VERSION ""

NS_ :

BS_:

BU_: Gateway EPS IBC RBU RWS PDCR

BO_ 256 ADV_2: 32 Gateway
 SG_ Checksum_ADV_2 : 0|8@1+ (1,0) [0|255] ""  EPS,IBC
 SG_ ADV_ErrorSt_EPS : 8|1@1+ (1,0) [0|1] ""  EPS
 SG_ ADV_AutoParkingModeReq : 9|3@1+ (1,0) [0|7] ""  EPS,PDCR
 SG_ ADV_AutoParkingRequestSt : 12|2@1+ (1,0) [0|3] ""  EPS,PDCR
 SG_ APA_DriverInterventionSt : 15|1@1+ (1,0) [0|1] ""  IBC
 SG_ ADV_ErrorSt_APA : 16|2@1+ (1,0) [0|3] ""  EPS
 SG_ ADV_ErrorSt_RPA : 18|2@1+ (1,0) [0|3] ""  EPS
 SG_ ADV_ErrorSt_AVP : 20|2@1+ (1,0) [0|3] ""  EPS
 SG_ ADV_ErrorSt_RVA : 22|2@1+ (1,0) [0|3] "" Vector__XXX
 SG_ ADV_WorkingSt_APA : 24|3@1+ (1,0) [0|7] ""  EPS
 SG_ ADV_WorkingSt_RPA : 27|3@1+ (1,0) [0|7] ""  EPS
 SG_ ADV_WorkingSt_AVP : 32|3@1+ (1,0) [0|7] ""  EPS
 SG_ APA_SecureRequest : 35|1@1+ (1,0) [0|1] ""  IBC
 SG_ APA_AutoParkingReq : 36|1@1+ (1,0) [0|1] ""  IBC,PDCR
 SG_ APA_DirectionCmd : 37|2@1+ (1,0) [0|3] ""  IBC
 SG_ ADV_SteeringWheelAngleRequest : 40|15@1+ (0.04375,0) [0|1433.55625] "°„"  EPS
 SG_ ADV_SteeringWheelAngleSignReques : 56|2@1+ (1,0) [0|3] ""  EPS
 SG_ ADV_SteeringWheelAngleControlReq : 58|2@1+ (1,0) [0|3] ""  EPS
 SG_ ADV_RearWheelAngleRequestSt : 62|2@1+ (1,0) [0|3] "" Vector__XXX
 SG_ ADV_RearWheelAngleRequest : 64|12@1+ (0.01,-20.48) [-20.48|20.47] "°„" Vector__XXX
 SG_ APA_BrakeFunctionMode : 76|4@1+ (1,0) [0|15] ""  IBC,PDCR
 SG_ APA_StopDistance : 80|12@1+ (1,0) [0|4095] "cm"  IBC
 SG_ APA_SpeedLimitation : 96|8@1+ (0.1,0) [0|15] "km/h"  IBC
 SG_ APA_FailureBrakeMode : 104|3@1+ (1,0) [0|7] ""  IBC
 SG_ LiveCounter_ADV_2 : 188|4@1+ (1,0) [0|15] "Pulse"  EPS,IBC
 SG_ SECOC_FV_ADV_2 : 192|16@1+ (1,0) [0|0] ""  IBC
 SG_ SECOC_TMAC_ADV_2 : 208|48@1+ (1,0) [0|0] ""  IBC

BO_ 546 ATC_2: 8 Gateway
 SG_ AmbientTemp : 24|8@1+ (0.5,-40) [-40|87.5] "°„C"  IBC

BO_ 586 DDCU_1: 8 Gateway
 SG_ DoorSt_FL : 2|1@1+ (1,0) [0|1] ""  IBC

BO_ 532 DMS_1: 8 Gateway
 SG_ DMS_ESCModeChangeCmd : 16|4@1+ (1,0) [0|15] ""  IBC
 SG_ DMS_EPSModeChangeCmd : 20|2@1+ (1,0) [0|3] ""  EPS

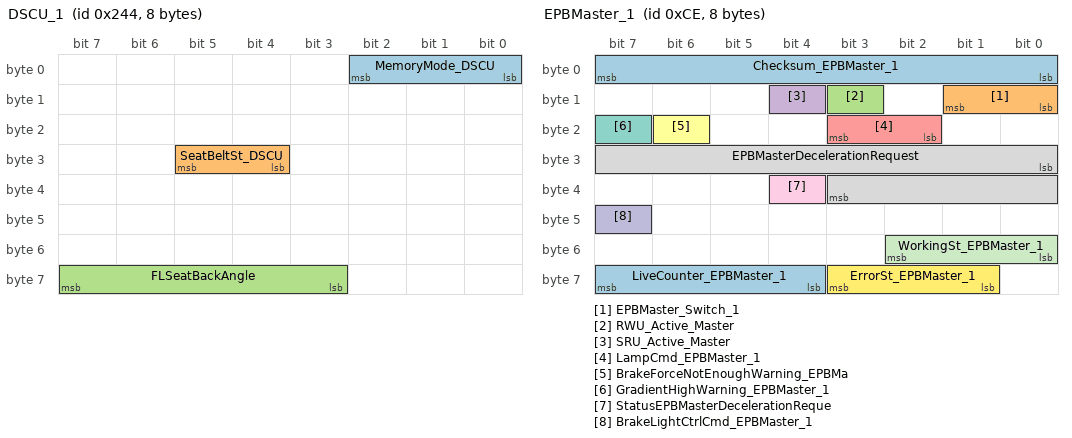
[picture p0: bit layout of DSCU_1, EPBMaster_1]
BO_ 580 DSCU_1: 8 Gateway
 SG_ MemoryMode_DSCU : 0|3@1+ (1,0) [0|7] "" Vector__XXX
 SG_ SeatBeltSt_DSCU : 28|2@1+ (1,0) [0|3] ""  IBC
 SG_ FLSeatBackAngle : 59|5@1+ (5,0) [0|100] "%" Vector__XXX

BO_ 233 EPBMasterReqToS: 8 Gateway
 SG_ PbcOutActuatorState_M : 8|3@1+ (1,0) [0|7] ""  PDCR
 SG_ PbcOutPadAdjustmentRequest_M : 12|1@1+ (1,0) [0|1] ""  PDCR
 SG_ PbcInHostAvailability_M : 13|2@1+ (1,0) [0|3] ""  PDCR
 SG_ PbcInApplyReleaseRequest_M : 16|4@1+ (1,0) [0|15] ""  PDCR
 SG_ PbcInRollerbenchActive_M : 20|1@1+ (1,0) [0|1] ""  PDCR
 SG_ PbcInDriveAwayIntentionIndicatio : 21|1@1+ (1,0) [0|1] ""  PDCR
 SG_ PbcEnableLineLock_M : 22|1@1+ (1,0) [0|1] ""  PDCR
 SG_ PbcEnableLineRelease_M : 23|1@1+ (1,0) [0|1] ""  PDCR
 SG_ EpbDegradedMode_M : 24|3@1+ (1,0) [0|7] ""  PDCR
 SG_ PbcDynApplyControlState_M : 28|4@1+ (1,0) [0|15] ""  PDCR
 SG_ PbcRollerbenchApplyControlState_ : 32|4@1+ (1,0) [0|15] ""  PDCR
 SG_ IsRelTchPt_M : 37|1@1+ (1,0) [0|1] ""  PDCR
 SG_ IsRWAAppEn_M : 38|1@1+ (1,0) [0|1] ""  PDCR
 SG_ IsRWARelEn_M : 39|1@1+ (1,0) [0|1] ""  PDCR
 SG_ RWACntrStpApp_M : 40|8@1+ (1,0) [0|255] "pulse"  PDCR
 SG_ CntrRWAAppHld_M : 48|8@1+ (1,0) [0|255] "pulse"  PDCR
 SG_ PbcRWAControlState_M : 56|4@1+ (1,0) [0|15] ""  PDCR

BO_ 206 EPBMaster_1: 8 Gateway
 SG_ Checksum_EPBMaster_1 : 0|8@1+ (1,0) [0|255] ""  IBC
 SG_ EPBMaster_Switch_1 : 8|2@1+ (1,0) [0|3] ""  IBC
 SG_ RWU_Active_Master : 11|1@1+ (1,0) [0|1] "" Vector__XXX
 SG_ SRU_Active_Master : 12|1@1+ (1,0) [0|1] "" Vector__XXX
 SG_ LampCmd_EPBMaster_1 : 18|2@1+ (1,0) [0|3] "" Vector__XXX
 SG_ BrakeForceNotEnoughWarning_EPBMa : 22|1@1+ (1,0) [0|1] "" Vector__XXX
 SG_ GradientHighWarning_EPBMaster_1 : 23|1@1+ (1,0) [0|1] "" Vector__XXX
 SG_ EPBMasterDecelerationRequest : 24|12@1+ (0.01,-20.47) [-20.47|20.48] "m/s2"  IBC
 SG_ StatusEPBMasterDecelerationReque : 36|1@1+ (1,0) [0|1] ""  IBC
 SG_ BrakeLightCtrlCmd_EPBMaster_1 : 47|1@1+ (1,0) [0|1] "" Vector__XXX
 SG_ WorkingSt_EPBMaster_1 : 48|3@1+ (1,0) [0|7] ""  IBC,RBU
 SG_ ErrorSt_EPBMaster_1 : 57|3@1+ (1,0) [0|7] ""  IBC
 SG_ LiveCounter_EPBMaster_1 : 60|4@1+ (1,0) [0|15] ""  IBC

BO_ 282 HAD_3: 32 Gateway
 SG_ Checksum_HAD_3 : 0|8@1+ (1,0) [0|255] ""  EPS,IBC
 SG_ HAD_AutoDrivingReq_L3 : 8|2@1+ (1,0) [0|3] ""  IBC,RBU
 SG_ HAD_SpeedChangeRequest_L3 : 10|11@1+ (0.01,-10.21) [-10.21|10.21] "m/s2"  IBC,RBU
 SG_ HAD_TimeGapSetting : 21|3@1+ (1,0) [0|7] "" Vector__XXX
 SG_ NOP_RearWheelAngleRequest : 24|12@1+ (0.01,-20.48) [-20.48|20.47] "°„" Vector__XXX
 SG_ NOP_RearWheelAngleRequestSt : 36|1@1+ (1,0) [0|1] "" Vector__XXX
 SG_ NOP_RearWheelReturnReq : 37|1@1+ (1,0) [0|1] "" Vector__XXX
 SG_ HAD_ObjectDetection : 38|1@1+ (1,0) [0|1] "" Vector__XXX
 SG_ HAD_TakeOverReq : 39|1@1+ (1,0) [0|1] "" Vector__XXX
 SG_ HAD_CruiseSpeedSetting_ACC : 40|8@1+ (1,0) [0|255] "km/h" Vector__XXX
 SG_ HAD_SysTextinfo : 48|4@1+ (1,0) [0|15] "" Vector__XXX
 SG_ HAD_LDWModeInd : 52|2@1+ (1,0) [0|3] "" Vector__XXX
 SG_ HAD_AutoLightModeReq : 54|1@1+ (1,0) [0|1] "" Vector__XXX
 SG_ HAD_HazardWarningLampRequest : 55|1@1+ (1,0) [0|1] "" Vector__XXX
 SG_ HAD_WorkingSt_LDW : 56|2@1+ (1,0) [0|3] "" Vector__XXX
 SG_ HAD_WarningCmd_LDW : 58|2@1+ (1,0) [0|3] "" Vector__XXX
 SG_ HAD_LDWLaneDetectSt : 64|2@1+ (1,0) [0|3] "" Vector__XXX
 SG_ HAD_SensitivityInd_LDW : 66|2@1+ (1,0) [0|3] "" Vector__XXX
 SG_ HAD_ErrorSt_LDW : 68|1@1+ (1,0) [0|1] "" Vector__XXX
 SG_ HAD_WorkingSt_FCW : 69|2@1+ (1,0) [0|3] "" Vector__XXX
 SG_ HAD_DriveAwayReq_L3 : 71|1@1+ (1,0) [0|1] ""  IBC
 SG_ HAD_StopReq_L3 : 72|1@1+ (1,0) [0|1] ""  IBC,RBU
 SG_ HAD_AccelerationPedalOverride : 73|1@1+ (1,0) [0|1] ""  IBC
 SG_ HAD_SensitivityInd_FCW : 74|2@1+ (1,0) [0|3] "" Vector__XXX
 SG_ HAD_FCWModeInd : 76|2@1+ (1,0) [0|3] "" Vector__XXX
 SG_ HAD_WiperAutoLeverReq : 78|1@1+ (1,0) [0|1] "" Vector__XXX
 SG_ HAD_VASFunctionInd : 79|1@1+ (1,0) [0|1] "" Vector__XXX
 SG_ HAD_SACCNotSatisfiedCondition : 80|3@1+ (1,0) [0|7] "" Vector__XXX
 SG_ HAD_LDW_SpeechControlFeedback : 83|3@1+ (1,0) [0|7] "" Vector__XXX
 SG_ HAD_IFCSystemError : 86|2@1+ (1,0) [0|3] "" Vector__XXX
 SG_ HAD_IFCCalibrationStatus : 88|2@1+ (1,0) [0|3] "" Vector__XXX
 SG_ HAD_WarningCmd_VAS : 90|1@1+ (1,0) [0|1] "" Vector__XXX
 SG_ HAD_LeftTurningLampRequest : 91|2@1+ (1,0) [0|3] "" Vector__XXX
 SG_ HAD_RightTurningLampRequest : 93|2@1+ (1,0) [0|3] "" Vector__XXX
 SG_ HAD_ValetModeStatus : 95|1@1+ (1,0) [0|1] "" Vector__XXX
 SG_ HAD_BrakeModeReq_L3 : 96|2@1+ (1,0) [0|3] ""  IBC,RBU
 SG_ HAD_DrivedownModeReq_L3 : 98|2@1+ (1,0) [0|3] ""  IBC,RBU
 SG_ HAD_SecureRequest_L3 : 100|2@1+ (1,0) [0|3] ""  IBC,RBU
 SG_ HAD_ErrorSt_AutoDriving_L3 : 102|1@1+ (1,0) [0|1] ""  IBC,RBU
 SG_ HAD_WorkingSt_NOP : 104|3@1+ (1,0) [0|7] ""  EPS
 SG_ HAD_ErrorSt_NOP : 107|2@1+ (1,0) [0|3] ""  EPS
 SG_ HAD_ErrorSt_HAD : 109|1@1+ (1,0) [0|1] ""  EPS,IBC,RBU
 SG_ HAD_AutoDrivingModeReq_NOP : 110|1@1+ (1,0) [0|1] ""  EPS
 SG_ HAD_AutoDrivingModeReq_NGP : 111|1@1+ (1,0) [0|1] ""  EPS
 SG_ HAD_SteeringWheelBlendingGain : 112|8@1+ (1,0) [0|100] "%"  EPS
 SG_ HAD_SteeringWheelAngleRequest : 120|15@1+ (0.04375,0) [0|1433.55625] "°„"  EPS
 SG_ HAD_SteeringWheelAngleSignReques : 136|2@1+ (1,0) [0|3] ""  EPS
 SG_ HAD_SteeringWheelAngleControlReq : 138|2@1+ (1,0) [0|3] ""  EPS
 SG_ HAD_WorkingSt_NGP : 144|3@1+ (1,0) [0|7] ""  EPS
 SG_ HAD_ErrorSt_NGP : 147|2@1+ (1,0) [0|3] ""  EPS
 SG_ LiveCounter_HAD_3 : 188|4@1+ (1,0) [0|15] ""  EPS,IBC
 SG_ SECOC_FV_HAD_3 : 192|16@1+ (1,0) [0|0] ""  IBC
 SG_ SECOC_TMAC_HAD_3 : 208|48@1+ (1,0) [0|0] ""  IBC

BO_ 151 HCU_2_10: 32 Gateway
 SG_ Checksum_HCU_2_10 : 0|8@1+ (1,0) [0|255] ""  EPS,IBC
 SG_ HCU_MCU1TMSpeed : 8|16@1+ (1,-30000) [-30000|30000] "rpm"  IBC
 SG_ HCU_FrontWheelActTorque : 24|14@1+ (1,-8000) [-8000|8000] "Nm"  EPS,IBC
 SG_ HCU_FrontWheelActTorqueSt : 39|1@1+ (1,0) [0|1] ""  EPS,IBC
 SG_ HCU_FrontWheelMaxDriveTorque : 40|13@1+ (1,0) [0|8000] "Nm"  IBC
 SG_ HCU_FrontWheelMaxDriveTorqueSt : 55|1@1+ (1,0) [0|1] ""  IBC
 SG_ HCU_FrontWheelMaxBrakeRegTorque : 56|13@1+ (1,-8000) [-8000|0] "Nm"  IBC
 SG_ HCU_FrontWheelMaxBrakeRegTorqSt : 71|1@1+ (1,0) [0|1] ""  IBC
 SG_ HCU_FrontWheelBrakeRegTorque : 72|13@1+ (1,-8000) [-8000|0] "Nm"  IBC
 SG_ HCU_FrontWheelBrakeRegTorqueSt : 87|1@1+ (1,0) [0|1] ""  IBC
 SG_ HCU_MCU2TMSpeed : 88|16@1+ (1,-30000) [-30000|30000] "rpm"  IBC
 SG_ HCU_RearWheelActTorque : 104|14@1+ (1,-8000) [-8000|8000] "Nm"  EPS,IBC
 SG_ HCU_RearWheelActTorqueSt : 119|1@1+ (1,0) [0|1] ""  EPS,IBC
 SG_ HCU_RearWheelMaxDriveTorque : 120|13@1+ (1,0) [0|8000] "Nm"  IBC
 SG_ HCU_RearWheelMaxDriveTorqueSt : 135|1@1+ (1,0) [0|1] ""  IBC
 SG_ HCU_RearWheelMaxBrakeRegTorque : 136|13@1+ (1,-8000) [-8000|0] "Nm"  IBC
 SG_ HCU_RearWheelMaxBrakeRegTorqSt : 151|1@1+ (1,0) [0|1] ""  IBC
 SG_ HCU_RearWheelBrakeRegTorque : 152|13@1+ (1,-8000) [-8000|0] "Nm"  IBC
 SG_ HCU_RearWheelBrakeRegTorqueSt : 167|1@1+ (1,0) [0|1] ""  IBC
 SG_ LiveCounter_HCU_2_10 : 252|4@1+ (1,0) [0|15] "Pulse"  EPS,IBC

BO_ 290 HCU_2_12: 16 Gateway
 SG_ Checksum_HCU_2_12 : 0|8@1+ (1,0) [0|255] ""  EPS,IBC
 SG_ HCU2_LeverInfo : 8|3@1+ (1,0) [0|7] ""  EPS,IBC
 SG_ HCU_HighVoltageStatus : 11|1@1+ (1,0) [0|1] ""  EPS,IBC
 SG_ HCU_AutoParkingResponse_HPA : 30|1@1+ (1,0) [0|1] ""  IBC
 SG_ HCU_AutoParkingResponse_AVP : 31|1@1+ (1,0) [0|1] ""  IBC
 SG_ HCU_AutoParkingResponse_APA : 32|1@1+ (1,0) [0|1] ""  IBC
 SG_ HCU_AutoParkingResponse_RPA : 33|1@1+ (1,0) [0|1] ""  IBC
 SG_ HCU_CapabilitySt_AutoParking : 34|2@1+ (1,0) [0|3] ""  IBC
 SG_ HCU_PowertrainErrorSt : 40|1@1+ (1,0) [0|1] ""  IBC
 SG_ HCU_PowertrainWorkSt : 41|3@1+ (1,0) [0|7] ""  IBC
 SG_ HCU_MCU1TorqueCtrlAvailableSt : 44|1@1+ (1,0) [0|1] ""  IBC
 SG_ HCU_MCU2TorqueCtrlAvailableSt : 46|1@1+ (1,0) [0|1] ""  IBC
 SG_ Livecounter_HCU_2_12 : 60|4@1+ (1,0) [0|15] "pulse"  EPS,IBC
 SG_ SECOC_FV_HCU_2_12 : 64|16@1+ (1,0) [0|0] ""  IBC
 SG_ SECOC_TMAC_HCU_2_12 : 80|48@1+ (1,0) [0|0] ""  IBC

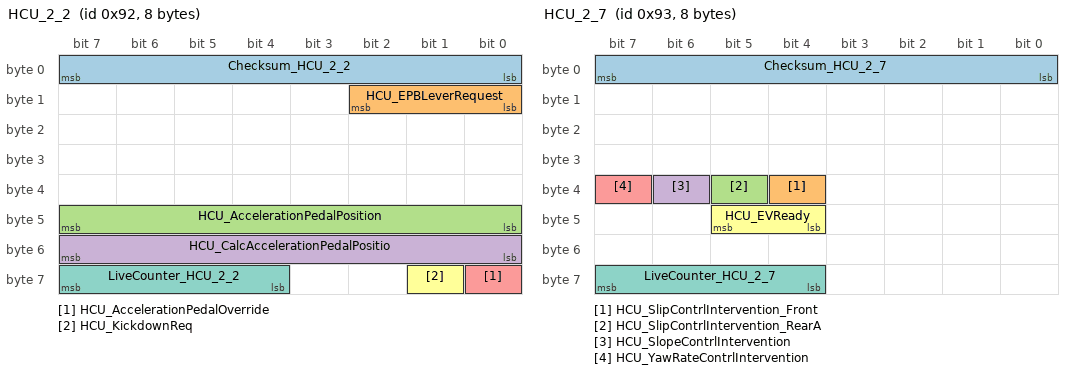
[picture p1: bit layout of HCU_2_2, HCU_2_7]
BO_ 146 HCU_2_2: 8 Gateway
 SG_ Checksum_HCU_2_2 : 0|8@1+ (1,0) [0|255] ""  EPS,IBC
 SG_ HCU_EPBLeverRequest : 8|3@1+ (1,0) [0|7] "" Vector__XXX
 SG_ HCU_AccelerationPedalPosition : 40|8@1+ (0.4,0) [0|100] "%"  EPS,IBC
 SG_ HCU_CalcAccelerationPedalPositio : 48|8@1+ (0.4,0) [0|100] "%"  EPS,IBC
 SG_ HCU_AccelerationPedalOverride : 56|1@1+ (1,0) [0|1] ""  IBC
 SG_ HCU_KickdownReq : 57|1@1+ (1,0) [0|1] "" Vector__XXX
 SG_ LiveCounter_HCU_2_2 : 60|4@1+ (1,0) [0|15] ""  EPS,IBC

BO_ 264 HCU_2_4: 24 Gateway
 SG_ Checksum_HCU_2_4 : 0|8@1+ (1,0) [0|255] ""  IBC
 SG_ HCU_DriverTorq_FrontWheel : 8|16@1+ (1,-3000) [-3000|13000] "Nm"  IBC
 SG_ HCU_AutoDrivingResponseSt_L12 : 24|1@1+ (1,0) [0|1] ""  IBC
 SG_ HCU_AutoDrivingResponseSt_L3 : 25|1@1+ (1,0) [0|1] ""  IBC
 SG_ HCU_CruiseControlSt : 26|2@1+ (1,0) [0|3] "" Vector__XXX
 SG_ HCU_CapabilitySt_AutoDriving : 28|2@1+ (1,0) [0|3] ""  IBC
 SG_ HCU_DriverTorq_RearWheel : 32|16@1+ (1,-3000) [-3000|13000] "Nm"  IBC
 SG_ HCU_GradientAccelerationPedal : 48|8@1+ (2,-253) [-253|257] "%/s" Vector__XXX
 SG_ LiveCounter_HCU_2_4 : 124|4@1+ (1,0) [0|15] ""  IBC

BO_ 147 HCU_2_7: 8 Gateway
 SG_ Checksum_HCU_2_7 : 0|8@1+ (1,0) [0|255] "" Vector__XXX
 SG_ HCU_SlipContrlIntervention_Front : 36|1@1+ (1,0) [0|1] ""  IBC
 SG_ HCU_SlipContrlIntervention_RearA : 37|1@1+ (1,0) [0|1] ""  IBC
 SG_ HCU_SlopeContrlIntervention : 38|1@1+ (1,0) [0|1] ""  IBC
 SG_ HCU_YawRateContrlIntervention : 39|1@1+ (1,0) [0|1] ""  IBC
 SG_ HCU_EVReady : 44|2@1+ (1,0) [0|3] ""  RWS
 SG_ LiveCounter_HCU_2_7 : 60|4@1+ (1,0) [0|15] "Pulse" Vector__XXX

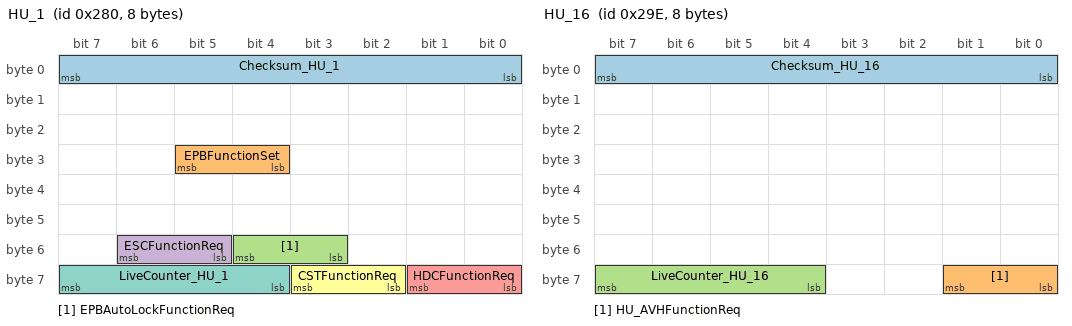
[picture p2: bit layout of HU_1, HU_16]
BO_ 640 HU_1: 8 Gateway
 SG_ Checksum_HU_1 : 0|8@1+ (1,0) [0|255] "" Vector__XXX
 SG_ EPBFunctionSet : 28|2@1+ (1,0) [0|3] "" Vector__XXX
 SG_ EPBAutoLockFunctionReq : 51|2@1+ (1,0) [0|3] "" Vector__XXX
 SG_ ESCFunctionReq : 53|2@1+ (1,0) [0|3] ""  IBC
 SG_ HDCFunctionReq : 56|2@1+ (1,0) [0|3] ""  IBC
 SG_ CSTFunctionReq : 58|2@1+ (1,0) [0|3] ""  IBC
 SG_ LiveCounter_HU_1 : 60|4@1+ (1,0) [0|15] "Pulse" Vector__XXX

BO_ 670 HU_16: 8 Gateway
 SG_ Checksum_HU_16 : 0|8@1+ (1,0) [0|255] "" Vector__XXX
 SG_ HU_AVHFunctionReq : 56|2@1+ (1,0) [0|3] ""  IBC
 SG_ LiveCounter_HU_16 : 60|4@1+ (1,0) [0|15] "Pulse" Vector__XXX

BO_ 656 IC_1: 8 Gateway
 SG_ OdometerValue : 24|25@1+ (0.1,0) [0|3355443.1] "km"  EPS,IBC,RWS

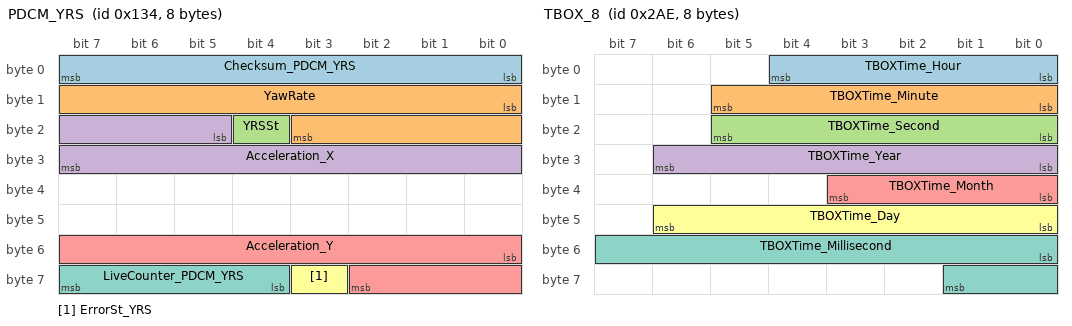
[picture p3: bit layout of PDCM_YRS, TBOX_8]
BO_ 308 PDCM_YRS: 8 Gateway
 SG_ Checksum_PDCM_YRS : 0|8@1+ (1,0) [0|255] ""  EPS
 SG_ YawRate : 8|12@1+ (0.05,-100) [-100|100] "deg/s"  EPS
 SG_ YRSSt : 20|1@1+ (1,0) [0|1] ""  EPS
 SG_ Acceleration_X : 21|11@1+ (0.027127,-21.593) [-21.593|21.593184] "m/s2"  EPS
 SG_ Acceleration_Y : 48|11@1+ (0.027127,-21.593) [-21.593|21.593184] "m/s2"  EPS
 SG_ ErrorSt_YRS : 59|1@1+ (1,0) [0|1] ""  EPS
 SG_ LiveCounter_PDCM_YRS : 60|4@1+ (1,0) [0|15] ""  EPS

BO_ 190 RVA_1: 16 Gateway
 SG_ Checksum_RVA_1 : 0|8@1+ (1,0) [0|255] ""  IBC,RWS
 SG_ SteerRearControlAngleReq_RVA : 8|12@1+ (0.01,-20.48) [-20.48|20.47] "°„"  RWS
 SG_ SteerRearControlSt_RVA : 20|2@1+ (1,0) [0|3] ""  RWS
 SG_ WorkingSt_RVA : 24|3@1+ (1,0) [0|7] ""  IBC
 SG_ BehaviorMode_RVA : 27|3@1+ (1,0) [0|7] "" Vector__XXX
 SG_ ErrorSt_RVA : 30|2@1+ (1,0) [0|3] "" Vector__XXX
 SG_ IBCControlAvailable_RVA : 32|1@1+ (1,0) [0|1] ""  IBC
 SG_ APAControlSt_RVA : 33|1@1+ (1,0) [0|1] "" Vector__XXX
 SG_ APAAbortFeedback_RVA : 34|5@1+ (1,0) [0|31] "" Vector__XXX
 SG_ SACCControlSt_RVA : 40|2@1+ (1,0) [0|3] "" Vector__XXX
 SG_ LKAControlSt_RVA : 42|2@1+ (1,0) [0|3] "" Vector__XXX
 SG_ NOPControlSt_RVA : 44|2@1+ (1,0) [0|3] "" Vector__XXX
 SG_ Livecounter_RVA_1 : 60|4@1+ (1,0) [0|15] ""  IBC,RWS
 SG_ SECOC_FV_RVA_1 : 64|16@1+ (1,0) [0|0] ""  IBC,RWS
 SG_ SECOC_TMAC_RVA_1 : 80|48@1+ (1,0) [0|0] ""  IBC,RWS

BO_ 686 TBOX_8: 8 Gateway
 SG_ TBOXTime_Hour : 0|5@1+ (1,0) [0|23] "hour"  RWS
 SG_ TBOXTime_Minute : 8|6@1+ (1,0) [0|59] "minute"  RWS
 SG_ TBOXTime_Second : 16|6@1+ (1,0) [0|59] "minute"  RWS
 SG_ TBOXTime_Year : 24|7@1+ (1,2011) [2011|2138] "year"  RWS
 SG_ TBOXTime_Month : 32|4@1+ (1,1) [1|12] "month"  RWS
 SG_ TBOXTime_Day : 40|7@1+ (1,1) [1|31] "day"  RWS
 SG_ TBOXTime_Millisecond : 48|10@1+ (1,0) [0|1000] "ms"  RWS

BO_ 1376 VDC397_MasterFVM: 16 Gateway
 SG_ SECOC_TripCounter : 0|24@1+ (1,0) [0|0] ""  IBC,RBU,RWS
 SG_ SECOC_ResetCounter : 24|16@1+ (1,0) [0|0] ""  IBC,RBU,RWS
 SG_ SECOC_Authenticator : 40|88@1+ (1,0) [0|0] ""  IBC,RBU,RWS

BO_ 280 VDC_1: 32 Gateway
 SG_ Checksum_VDC_1 : 0|8@1+ (1,0) [0|255] ""  EPS,IBC
 SG_ VDC_AutoDrivingReq_L12 : 8|2@1+ (1,0) [0|3] ""  IBC
 SG_ VDC_DecelerationReqEnable_AEB : 10|2@1+ (1,0) [0|3] ""  IBC
 SG_ VDC_SteeringTorqueRequestSign : 12|1@1+ (1,0) [0|1] ""  EPS
 SG_ VDC_SteeringTorqueReqSt : 13|1@1+ (1,0) [0|1] ""  EPS
 SG_ VDC_Intervention_LKA : 14|2@1+ (1,0) [0|3] ""  EPS
 SG_ VDC_WorkingSt_LKA : 16|2@1+ (1,0) [0|3] ""  EPS
 SG_ VDC_ErrorSt_LKA : 18|1@1+ (1,0) [0|1] ""  EPS
 SG_ VDC_AccelerationPedalOverride : 19|1@1+ (1,0) [0|1] ""  IBC
 SG_ VDC_WorkingSt_AEB_L12 : 20|2@1+ (1,0) [0|3] ""  IBC
 SG_ VDC_ErrorSt_AEB_L12 : 22|1@1+ (1,0) [0|1] ""  IBC
 SG_ VDC_ErrorSt_ACC_L12 : 23|1@1+ (1,0) [0|1] ""  IBC
 SG_ VDC_SpeedChangeRequest_L12 : 24|11@1+ (0.01,-10.21) [-10.21|10.21] "m/s2"  IBC
 SG_ VDC_DriveAwayReq_L12 : 35|1@1+ (1,0) [0|1] ""  IBC
 SG_ VDC_StopReq_L12 : 36|1@1+ (1,0) [0|1] ""  IBC
 SG_ VDC_WorkingSt_ACC_L12 : 37|3@1+ (1,0) [0|7] ""  IBC
 SG_ VDC_TakeOverTip_LCA : 40|1@1+ (1,0) [0|1] "" Vector__XXX
 SG_ VDC_ABPReq_L12 : 41|1@1+ (1,0) [0|1] ""  IBC
 SG_ VDC_AWBReq_L12 : 42|1@1+ (1,0) [0|1] ""  IBC
 SG_ VDC_AWBlevel_L12 : 43|3@1+ (1,0) [0|7] ""  IBC
 SG_ VDC_CruiseModeFunctionInd : 46|2@1+ (1,0) [0|3] "" Vector__XXX
 SG_ VDC_BrakeModeReq_L12 : 48|2@1+ (1,0) [0|3] ""  IBC
 SG_ VDC_DrivedownModeReq_L12 : 50|2@1+ (1,0) [0|3] ""  IBC
 SG_ VDC_SecureRequest_L12 : 52|1@1+ (1,0) [0|1] ""  IBC
 SG_ VDC_AEBSensitivity_L12 : 53|2@1+ (1,0) [0|3] "" Vector__XXX
 SG_ VDC_ErrorSt_LCA : 55|1@1+ (1,0) [0|1] "" Vector__XXX
 SG_ VDC_AutoDrivingReq : 56|2@1+ (1,0) [0|3] "" Vector__XXX
 SG_ VDC_AutoDrivingLevel : 58|2@1+ (1,0) [0|3] "" Vector__XXX
 SG_ VDC_HandsOffTip_LCA : 60|2@1+ (1,0) [0|3] "" Vector__XXX
 SG_ VDC_ErrorSt_SACC : 62|2@1+ (1,0) [0|3] ""  EPS
 SG_ VDC_DecelerationReq_AEB : 64|10@1+ (0.01,-10.21) [-10.21|0.2] "m/s2"  IBC
 SG_ VDC_WorkingSt_LCA : 75|3@1+ (1,0) [0|7] "" Vector__XXX
 SG_ VDC_LDWSteeringVibrationReq : 78|1@1+ (1,0) [0|1] "" Vector__XXX
 SG_ VDC_ErrorSt_VDC : 79|1@1+ (1,0) [0|1] ""  EPS
 SG_ VDC_SteeringTorqueRequest : 80|10@1+ (0.01,0) [0|10] "Nm"  EPS
 SG_ VDC_AutoDrivingModeReq : 90|3@1+ (1,0) [0|7] ""  EPS
 SG_ VDC_WorkingSt_SACC : 93|3@1+ (1,0) [0|7] ""  EPS
 SG_ VDC_WorkingSt_DCLC : 96|3@1+ (1,0) [0|7] "" Vector__XXX
 SG_ VDC_ErrorSt_EMA : 100|1@1+ (1,0) [0|1] ""  EPS
 SG_ VDC_WorkingSt_EMA : 101|3@1+ (1,0) [0|7] ""  EPS
 SG_ VDC_SteeringWheelAngleRequest : 104|15@1+ (0.04375,0) [0|1433.55625] "°„"  EPS
 SG_ SACC_RearWheelAngleRequestSt : 119|1@1+ (1,0) [0|1] "" Vector__XXX
 SG_ VDC_SteeringWheelAngleSignReques : 120|2@1+ (1,0) [0|3] ""  EPS
 SG_ VDC_SteeringWheelAngleControlReq : 122|2@1+ (1,0) [0|3] ""  EPS
 SG_ SACC_RearWheelReturnReq : 124|1@1+ (1,0) [0|1] "" Vector__XXX
 SG_ LKA_RearWheelAngleRequestSt : 125|1@1+ (1,0) [0|1] "" Vector__XXX
 SG_ LKA_RearWheelReturnReq : 126|1@1+ (1,0) [0|1] "" Vector__XXX
 SG_ VDC_AutoDrivingModeReq_EMA : 127|1@1+ (1,0) [0|1] ""  EPS
 SG_ VDC_SteeringWheelBlendingGain : 128|8@1+ (1,0) [0|100] "%"  EPS
 SG_ VDC_SteeringMaxTorqueRequest : 136|10@1+ (0.01,0) [0|10] "Nm"  EPS
 SG_ SACC_RearWheelAngleRequest : 152|12@1+ (0.01,-20.48) [-20.48|20.47] "°„" Vector__XXX
 SG_ LKA_RearWheelAngleRequest : 168|12@1+ (0.01,-20.48) [-20.48|20.47] "°„" Vector__XXX
 SG_ VDC_WorkingSt_FCW : 180|2@1+ (1,0) [0|3] ""  IBC
 SG_ VDC_ErrorSt_FCW : 182|1@1+ (1,0) [0|1] ""  IBC
 SG_ VDC_ErrorSt_L3Backup : 183|1@1+ (1,0) [0|1] ""  EPS,IBC
 SG_ VDC_WorkingSt_L3Backup : 184|3@1+ (1,0) [0|7] ""  EPS
 SG_ LiveCounter_VDC_1 : 188|4@1+ (1,0) [0|15] ""  EPS,IBC

CM_ SG_ 256 ADV_ErrorSt_EPS "This signal indicates ADV is error or not.If the value of this signal is °∞Error°Æ,EPS shoud ignore this message and rESCond the message from ADV.";
CM_ SG_ 256 ADV_AutoParkingModeReq "Auto parking mode request";
CM_ SG_ 256 ADV_AutoParkingRequestSt "Auto Parking request status";
CM_ SG_ 256 APA_DriverInterventionSt "This signal indicates if driver inervention during APA/RPA/AVP/HPA function";
CM_ SG_ 256 ADV_ErrorSt_APA "ADV system capbility for APA";
CM_ SG_ 256 ADV_ErrorSt_RPA "ADV system capbility for RPA";
CM_ SG_ 256 ADV_ErrorSt_AVP "ADV system capbility for AVP";
CM_ SG_ 256 ADV_ErrorSt_RVA "This signal indicates ADV is error or not.If the value of this signal is °∞Error°Æ,RVA shoud ignore this message and rESCond the message from ADV.";
CM_ SG_ 256 ADV_WorkingSt_APA "This signal indicates the APA working status.";
CM_ SG_ 256 ADV_WorkingSt_RPA "This signal indicates the RPA working status.";
CM_ SG_ 256 ADV_WorkingSt_AVP "This signal indicates the AVP working status.";
CM_ SG_ 256 APA_SecureRequest "In the emergency condition,APA requests P locking and push EPB.
This signal is used for L1L2L3 function.";
CM_ SG_ 256 APA_AutoParkingReq "HAD request to active auto parking function.
";
CM_ SG_ 256 APA_DirectionCmd "The heading direction command from HAD/ADV in APA/RPA function.";
CM_ SG_ 256 ADV_SteeringWheelAngleRequest "Steering Wheel Angle Request";
CM_ SG_ 256 ADV_SteeringWheelAngleSignReques "Steering Wheel Angle Sign Request";
CM_ SG_ 256 ADV_SteeringWheelAngleControlReq "Steering Wheel Angle Control Request";
CM_ SG_ 256 ADV_RearWheelAngleRequestSt "This signal indicates the request status of  APA,AVP,RPA,HPA";
CM_ SG_ 256 ADV_RearWheelAngleRequest "This signal indicates the absolute value of APA,AVP,RPA,HPA rear wheel angle request";
CM_ SG_ 256 APA_BrakeFunctionMode "This signal indicate which function mode the ESC enters";
CM_ SG_ 256 APA_StopDistance "This signal inform the ESC the parking target distance ";
CM_ SG_ 256 APA_SpeedLimitation "This signal inform ESC the velocity maximum";
CM_ SG_ 256 APA_FailureBrakeMode "This signal indicates the brake mode when APA/RPA failure";
CM_ SG_ 256 SECOC_FV_ADV_2 "Fresh value signal for SECOC. The signal shall be proceeded following the byte order requirement in FAW-CYS-0033, i.e. SECOC spec";
CM_ SG_ 256 SECOC_TMAC_ADV_2 "Truncated MAC signal for SECOC. The signal shall be proceeded following the byte order requirement in FAW-CYS-0033, i.e. SECOC spec";
CM_ SG_ 546 AmbientTemp "The signal indicate ambient temperature.";
CM_ SG_ 586 DoorSt_FL "This signal indicates the state of driver door.";
CM_ SG_ 532 DMS_ESCModeChangeCmd "The command of changing ESC working mode from Drive Mode Selection ECU";
CM_ SG_ 532 DMS_EPSModeChangeCmd "The command of changing EPS working mode from Drive Mode Selection ECU";
CM_ SG_ 580 MemoryMode_DSCU "This signal shows operation of seat position memory.";
CM_ SG_ 580 SeatBeltSt_DSCU "The signal is sent to indicate the FL Seat Belt is buckled or Unbuckled.";
CM_ SG_ 580 FLSeatBackAngle "The signal indicates the current backrest angle of front left seat.";
CM_ SG_ 233 PbcOutActuatorState_M "The signal indicates the PBC out actuator  status of EPB master.";
CM_ SG_ 233 PbcOutPadAdjustmentRequest_M "The signal indicates the PBC out pad adjustment request of EPB master.";
CM_ SG_ 233 PbcInHostAvailability_M "The signal indicates the PBC in host availability of EPB master.";
CM_ SG_ 233 PbcInApplyReleaseRequest_M "The signal indicates the PBC in request of EPB master.";
CM_ SG_ 233 PbcInRollerbenchActive_M "The signal indicates the brake light control command of EPB master.";
CM_ SG_ 233 PbcInDriveAwayIntentionIndicatio "The signal indicates the PBC in drive-away intention indication of EPB master.";
CM_ SG_ 233 PbcEnableLineLock_M "The signal indicates the PBC enable line lock status of EPB master of EPB master.";
CM_ SG_ 233 PbcEnableLineRelease_M "The signal indicates the PBC enable line release status of EPB master of EPB master.";
CM_ SG_ 233 EpbDegradedMode_M "The signal indicates the degrade status of EPB master.";
CM_ SG_ 233 PbcDynApplyControlState_M "The signal indicates the PBC dynamic apply control state of EPB master.";
CM_ SG_ 233 PbcRollerbenchApplyControlState_ "The signal indicates the PBC roller-bench apply control state of EPB master.
";
CM_ SG_ 233 IsRelTchPt_M "The signal indicates the brake pad diviation status of  EPB master.";
CM_ SG_ 233 IsRWAAppEn_M "The signal indicates the RWA apply enable status of  EPB master.";
CM_ SG_ 233 IsRWARelEn_M "The signal indicates the RWA release enable status of  EPB master.";
CM_ SG_ 233 RWACntrStpApp_M "The signal indicates the RWA stp apply counter.";
CM_ SG_ 233 CntrRWAAppHld_M "The signal indicates the RWU App hold counter.";
CM_ SG_ 233 PbcRWAControlState_M "The signal indicates the PBC RWA control state of EPB master.
";
CM_ SG_ 206 Checksum_EPBMaster_1 "The checksum is used to check whether the data from the CPU buffer are shifted without transmission errors to the CAN communication controller buffer and vice versa.";
CM_ SG_ 206 EPBMaster_Switch_1 "This signal indicates if the switch of EPB";
CM_ SG_ 206 RWU_Active_Master "Indicates if the RWU is active or not.";
CM_ SG_ 206 SRU_Active_Master "Indicates if the SRU is active or not.";
CM_ SG_ 206 LampCmd_EPBMaster_1 "The signal indicates the lamp indication of EPB.";
CM_ SG_ 206 BrakeForceNotEnoughWarning_EPBMa "This signal is warning command for EPB warning.
Indicates the brake force not enough";
CM_ SG_ 206 GradientHighWarning_EPBMaster_1 "This signal is warning command for EPB warning.
Indicates the gradient is too high ";
CM_ SG_ 206 EPBMasterDecelerationRequest "EPB deceleration request for wheel brake";
CM_ SG_ 206 StatusEPBMasterDecelerationReque "Status of the deceleration request from EPB in case of no request  EPBDecelerationRequest=0xFFE.";
CM_ SG_ 206 BrakeLightCtrlCmd_EPBMaster_1 "The signal indicates the brake light control command.";
CM_ SG_ 206 WorkingSt_EPBMaster_1 "The signal indicates the working status of EPB.";
CM_ SG_ 206 ErrorSt_EPBMaster_1 "The signal indicates the working status of EPB master node.";
CM_ SG_ 206 LiveCounter_EPBMaster_1 "The Livecounter is used to check the signal consistency of the messages . If the signals are consecutive, the LiveCounter should also be sequential in the way 0, 1, 2 ...X(depends on E2E usage), 0, 1 °≠";
CM_ SG_ 282 Checksum_HAD_3 "The checksum is used to check whether the data from the CPU buffer are shifted without transmission errors to the CAN communication controller buffer and vice versa.";
CM_ SG_ 282 HAD_AutoDrivingReq_L3 "This signal indicates the acceleration or deceleration command is from L1L2 function or L3 function.";
CM_ SG_ 282 HAD_SpeedChangeRequest_L3 "This signal is the value of acceleration request or deceleration request(L3).";
CM_ SG_ 282 HAD_TimeGapSetting "The cruise time gap  is setted according to the control requests from the driver.";
CM_ SG_ 282 NOP_RearWheelAngleRequest "This signal indicates the absolute value of NOP rear wheel angle request";
CM_ SG_ 282 NOP_RearWheelAngleRequestSt "This signal indicates the request status of NOP";
CM_ SG_ 282 NOP_RearWheelReturnReq "This signal indicates the return to 0 request status of NOP";
CM_ SG_ 282 HAD_ObjectDetection "This signal is an ahead target object detected by ACC, to inform the driver.";
CM_ SG_ 282 HAD_TakeOverReq "This signal indicates the request for driver take over if the limits of the ACC /SACC control reaches, ";
CM_ SG_ 282 HAD_CruiseSpeedSetting_ACC "The signal indicates the target speed desired by the driver in ACC cruise mode.";
CM_ SG_ 282 HAD_SysTextinfo "The systerm text information for driver which is displayed in dashboard.";
CM_ SG_ 282 HAD_LDWModeInd "This signal is used to indicates the configure result of LDW function.";
CM_ SG_ 282 HAD_AutoLightModeReq "This signal indicates HAD/HAD request BCM to active the automatic light mode.";
CM_ SG_ 282 HAD_HazardWarningLampRequest "Hazard Warning Lamp request from LCA";
CM_ SG_ 282 HAD_WorkingSt_LDW "This signal indicates the LDW working status.";
CM_ SG_ 282 HAD_WarningCmd_LDW "This signal is warning command for the warning side of lane.";
CM_ SG_ 282 HAD_LDWLaneDetectSt "This signal indicate system lane mark detection status";
CM_ SG_ 282 HAD_SensitivityInd_LDW "This signal indicates current sensitivity of LDW.";
CM_ SG_ 282 HAD_ErrorSt_LDW "This signal indicates the LDW error status.";
CM_ SG_ 282 HAD_WorkingSt_FCW "This signal indicates the FCW system working status.";
CM_ SG_ 282 HAD_DriveAwayReq_L3 "This signal indicates HAD controller request vehicle drive off, ";
CM_ SG_ 282 HAD_StopReq_L3 "This signal indicates HAD controller request vehicle decelerate to standtill,";
CM_ SG_ 282 HAD_AccelerationPedalOverride "This signal indicates the torque demanded by the driver is higher than the torque demanded by NOP.";
CM_ SG_ 282 HAD_SensitivityInd_FCW "This signal indicates current sensitivity of FCW.";
CM_ SG_ 282 HAD_FCWModeInd "This signal is used to indicates the configure result of FCW function.";
CM_ SG_ 282 HAD_WiperAutoLeverReq "This signal indicates that HAD/HAD request BCM1 to turn the wiper to auto lever mode.";
CM_ SG_ 282 HAD_VASFunctionInd "This signal indicates setting result of the configuration of VAS(Vehicle Ahead Start) function.";
CM_ SG_ 282 HAD_SACCNotSatisfiedCondition "This signal indicates the conditions that cant active SACC/ACC function";
CM_ SG_ 282 HAD_LDW_SpeechControlFeedback "This signal indicates the speech control feedback of LDW function setting";
CM_ SG_ 282 HAD_IFCSystemError "This signal indicates the IFC error status.";
CM_ SG_ 282 HAD_IFCCalibrationStatus "This signal indicates the IFC calibration status.";
CM_ SG_ 282 HAD_WarningCmd_VAS "This signal is warning command for the VAS(Vehicle Ahead Start) function.";
CM_ SG_ 282 HAD_LeftTurningLampRequest "Left Turning Lamp request";
CM_ SG_ 282 HAD_RightTurningLampRequest "Right Turning Lamp request";
CM_ SG_ 282 HAD_ValetModeStatus "Indicates the valet mode status";
CM_ SG_ 282 HAD_BrakeModeReq_L3 "This signal indicate HAD request to brake cosily or urgently.
This signal is only used for L3 function";
CM_ SG_ 282 HAD_DrivedownModeReq_L3 "HAD request to quit autodriving funciton.
This signal is only used for L3 function.";
CM_ SG_ 282 HAD_SecureRequest_L3 "HAD request to stop the car safely.
This signal is only used for L3 function";
CM_ SG_ 282 HAD_ErrorSt_AutoDriving_L3 "This signal indicates the L3 autodriving function error status.
This signal is only used for L3 function";
CM_ SG_ 282 HAD_WorkingSt_NOP "This signal indicates the NOP working status.";
CM_ SG_ 282 HAD_ErrorSt_NOP "HAD system capbility for NOP";
CM_ SG_ 282 HAD_ErrorSt_HAD "This signal indicates HAD is error or not.If the value of this signal is °∞Error°Æ,EPS shoud ignore this message and respond the message from HAD.";
CM_ SG_ 282 HAD_AutoDrivingModeReq_NOP "This signal is the Source of Angal request to EPS of NOP function";
CM_ SG_ 282 HAD_AutoDrivingModeReq_NGP "This signal is the Source of Angal request to EPS of NGP function";
CM_ SG_ 282 HAD_SteeringWheelBlendingGain "Blending Gain Factor";
CM_ SG_ 282 HAD_SteeringWheelAngleRequest "Steering Wheel Angle Request";
CM_ SG_ 282 HAD_SteeringWheelAngleSignReques "Steering Wheel Angle Sign Request";
CM_ SG_ 282 HAD_SteeringWheelAngleControlReq "Steering Wheel Angle Control Request";
CM_ SG_ 282 HAD_WorkingSt_NGP "This signal indicates the NGP working status.";
CM_ SG_ 282 HAD_ErrorSt_NGP "HAD system capbility for NGP";
CM_ SG_ 282 LiveCounter_HAD_3 "The Livecounter is used to check the signal consistency of the messages . If the signals are consecutive, the LiveCounter should also be sequential in the way 0, 1, 2 ...X(depends on E2E usage), 0, 1 °≠";
CM_ SG_ 282 SECOC_FV_HAD_3 "Fresh value signal for SECOC. The signal shall be proceeded following the byte order requirement in FAW-CYS-0033, i.e. SECOC spec";
CM_ SG_ 282 SECOC_TMAC_HAD_3 "Truncated MAC signal for SECOC. The signal shall be proceeded following the byte order requirement in FAW-CYS-0033, i.e. SECOC spec";
CM_ SG_ 151 Checksum_HCU_2_10 "The checksum is used to check whether the data from the CPU buffer are shifted without transmission errors to the CAN communication controller buffer and vice versa.";
CM_ SG_ 151 HCU_MCU1TMSpeed "The TM Speed of MCU1.Positive value means forward, negative value means backward.";
CM_ SG_ 151 HCU_FrontWheelActTorque "The torque of the power system acting on the wheel ends of the front axle";
CM_ SG_ 151 HCU_FrontWheelActTorqueSt "The torque state of the power system acting on the wheel end of the front axle";
CM_ SG_ 151 HCU_FrontWheelMaxDriveTorque "The Maximum driving torque capacity at the wheel end of the front axle";
CM_ SG_ 151 HCU_FrontWheelMaxDriveTorqueSt "The Maximum driving torque status capacity at the wheel end of the front axle";
CM_ SG_ 151 HCU_FrontWheelMaxBrakeRegTorque "The Maximum brake recovery capacity torque at the wheel end of the front axle";
CM_ SG_ 151 HCU_FrontWheelMaxBrakeRegTorqSt "The Maximum brake recovery capacity torque status at the wheel end of the front axle";
CM_ SG_ 151 HCU_FrontWheelBrakeRegTorque "Front axle wheel end braking energy recovery torque (not including coasting recovery)";
CM_ SG_ 151 HCU_FrontWheelBrakeRegTorqueSt "Front axle wheel end braking energy recovery torque state";
CM_ SG_ 151 HCU_MCU2TMSpeed "The TM Speed of MCU2";
CM_ SG_ 151 HCU_RearWheelActTorque "The torque of the power system acting on the wheel ends of the Rear axle";
CM_ SG_ 151 HCU_RearWheelActTorqueSt "The torque state of the power system acting on the wheel end of the Rear axle";
CM_ SG_ 151 HCU_RearWheelMaxDriveTorque "The Maximum driving torque capacity at the wheel end of the Rear axle";
CM_ SG_ 151 HCU_RearWheelMaxDriveTorqueSt "The Maximum driving torque status capacity at the wheel end of the Rear axle";
CM_ SG_ 151 HCU_RearWheelMaxBrakeRegTorque "The Maximum brake recovery capacity torque at the wheel end of the Rear axle";
CM_ SG_ 151 HCU_RearWheelMaxBrakeRegTorqSt "The Maximum brake recovery capacity torque status at the wheel end of the Rear axle";
CM_ SG_ 151 HCU_RearWheelBrakeRegTorque "Rear axle wheel end braking energy recovery torque (not including coasting recovery)";
CM_ SG_ 151 HCU_RearWheelBrakeRegTorqueSt "Rear axle wheel end braking energy recovery torque state";
CM_ SG_ 151 LiveCounter_HCU_2_10 "The Livecounter is used to check the signal consistency of the messages . If the signals are consecutive, the LiveCounter should also be sequential in the way 0, 1, 2 °≠X(depends on E2E usage), 0, 1 °≠";
CM_ SG_ 290 Checksum_HCU_2_12 "The checksum is used to check whether the data from the CPU buffer are shifted without transmission errors to the CAN communication controller buffer and vice versa.";
CM_ SG_ 290 HCU2_LeverInfo "This signal indicate Lever info for display";
CM_ SG_ 290 HCU_HighVoltageStatus "The vehcle high-voltage working status";
CM_ SG_ 290 HCU_AutoParkingResponse_HPA "The signal indicates if HCU can response the HPA autoparking request";
CM_ SG_ 290 HCU_AutoParkingResponse_AVP "The signal indicates if HCU can response the AVP autoparking request";
CM_ SG_ 290 HCU_AutoParkingResponse_APA "The signal indicates if HCU can response the APA autoparking request";
CM_ SG_ 290 HCU_AutoParkingResponse_RPA "The signal indicates if HCU can response the L3 autoparking request";
CM_ SG_ 290 HCU_CapabilitySt_AutoParking "The signal is the capability of HCU for auto parking functions.";
CM_ SG_ 290 HCU_PowertrainErrorSt "This signal indicates the powertrain system error status.";
CM_ SG_ 290 HCU_PowertrainWorkSt "This signal indicates the powertrain system working status.";
CM_ SG_ 290 HCU_MCU1TorqueCtrlAvailableSt "This signal indicates whether the MCU1 is available for external torque request.";
CM_ SG_ 290 HCU_MCU2TorqueCtrlAvailableSt "This signal indicates whether the MCU2 is available for external torque request.";
CM_ SG_ 290 Livecounter_HCU_2_12 "The Livecounter is used to check the signal consistency of the messages . If the signals are consecutive, the LiveCounter should also be sequential in the way 0, 1, 2 ...X(depends on E2E usage), 0, 1 °≠";
CM_ SG_ 290 SECOC_FV_HCU_2_12 "Fresh value signal for SECOC. The signal shall be proceeded following the byte order requirement in FAW-CYS-0033, i.e. SECOC spec";
CM_ SG_ 290 SECOC_TMAC_HCU_2_12 "Truncated MAC signal for SECOC. The signal shall be proceeded following the byte order requirement in FAW-CYS-0033, i.e. SECOC spec";
CM_ SG_ 146 Checksum_HCU_2_2 "The checksum is used to check whether the data from the CPU buffer are shifted without transmission errors to the CAN communication controller buffer and vice versa.";
CM_ SG_ 146 HCU_EPBLeverRequest "This signal is used for the EPB locking request of HCU. For those vehicles not configured with Epark, this signal will be used to inform EPB the lever transformation. Then EPB will lock or release the caliper according to the request.";
CM_ SG_ 146 HCU_AccelerationPedalPosition "This signal indicates the actual acceleration pedal position";
CM_ SG_ 146 HCU_CalcAccelerationPedalPositio "This signal indicates the calculated acceleration pedal position in cruise control mode.";
CM_ SG_ 146 HCU_AccelerationPedalOverride "This signal indicates the torque demanded by the driver is higher than the torque demanded by ACC.";
CM_ SG_ 146 HCU_KickdownReq "This signal is used to show the fast acceleration request from the driver. ";
CM_ SG_ 146 LiveCounter_HCU_2_2 "The Livecounter is used to check the signal consistency of the messages . If the signals are consecutive, the LiveCounter should also be sequential in the way 0, 1, 2 ...X(depends on E2E usage), 0, 1 °≠";
CM_ SG_ 264 Checksum_HCU_2_4 "The checksum is used to check whether the data from the CPU buffer are shifted without transmission errors to the CAN communication controller buffer and vice versa.";
CM_ SG_ 264 HCU_DriverTorq_FrontWheel "The indicated driver torque for front wheel.";
CM_ SG_ 264 HCU_AutoDrivingResponseSt_L12 "The signal indicates if HCU can response the L12 autodriving request or not.";
CM_ SG_ 264 HCU_AutoDrivingResponseSt_L3 "The signal indicates if HCU can response the L3 autodriving request or not.";
CM_ SG_ 264 HCU_CruiseControlSt "The cruise control status is controlled  according to the cruise control requests from the driver.";
CM_ SG_ 264 HCU_CapabilitySt_AutoDriving "The signal is the capability of HCU for auto driving functions.";
CM_ SG_ 264 HCU_DriverTorq_RearWheel "The indicated driver torque for rear wheel.";
CM_ SG_ 264 HCU_GradientAccelerationPedal "Gradient of the standardized acceleration pedal angle";
CM_ SG_ 264 LiveCounter_HCU_2_4 "The Livecounter is used to check the signal consistency of the messages . If the signals are consecutive, the LiveCounter should also be sequential in the way 0, 1, 2 ...X(depends on E2E usage), 0, 1 °≠";
CM_ SG_ 147 Checksum_HCU_2_7 "The checksum is used to check whether the data from the CPU buffer are shifted without transmission errors to the CAN communication controller buffer and vice versa.";
CM_ SG_ 147 HCU_SlipContrlIntervention_Front "This signal indicates  if  HCU slip control function(front axle) is intervention or not. Now this signal is reserved for IBC. ";
CM_ SG_ 147 HCU_SlipContrlIntervention_RearA "This signal indicates  if  HCU slip control function(rear axle) is intervention or not. Now this signal is reserved for IBC. ";
CM_ SG_ 147 HCU_SlopeContrlIntervention "This signal indicates  if  HCU slop control function is intervention or not. Now this signal is reserved for IBC. ";
CM_ SG_ 147 HCU_YawRateContrlIntervention "This signal indicates  if  HCU yaw rate control function is intervention or not. Now this signal is reserved for IBC. ";
CM_ SG_ 147 HCU_EVReady "EV system can run or not";
CM_ SG_ 147 LiveCounter_HCU_2_7 "The Livecounter is used to check the signal consistency of the messages . If the signals are consecutive, the LiveCounter should also be sequential in the way 0, 1, 2 ...X(depends on E2E usage), 0, 1 °≠";
CM_ SG_ 640 Checksum_HU_1 "The checksum is used to check whether the data from the CPU buffer are shifted without transmission errors to the CAN communication controller buffer and vice versa.";
CM_ SG_ 640 EPBFunctionSet "This signal is used to set EPB function.";
CM_ SG_ 640 EPBAutoLockFunctionReq "This signal is used to modify the configuration of EPB AutoLock function.";
CM_ SG_ 640 ESCFunctionReq "This signal is used to modify the configuration of ESC function.";
CM_ SG_ 640 HDCFunctionReq "This signal is used to modify the configuration of HDC function.";
CM_ SG_ 640 CSTFunctionReq "This signal is used to modify the configuration of CST function.";
CM_ SG_ 640 LiveCounter_HU_1 "The Livecounter is used to check the signal consistency of the messages . If the signals are consecutive, the LiveCounter should also be sequential in the way 0, 1, 2 ...X(depends on E2E usage), 0, 1 °≠";
CM_ SG_ 670 Checksum_HU_16 "The checksum is used to check whether the data from the CPU buffer are shifted without transmission errors to the CAN communication controller buffer and vice versa.";
CM_ SG_ 670 HU_AVHFunctionReq "This signal is used to modify the configuration of AVH function.";
CM_ SG_ 670 LiveCounter_HU_16 "The Livecounter is used to check the signal consistency of the messages . If the signals are consecutive, the LiveCounter should also be sequential in the way 0, 1, 2 ...X(depends on E2E usage), 0, 1 °≠";
CM_ SG_ 656 OdometerValue "This signal is drive distance since prime start .";
CM_ SG_ 308 Checksum_PDCM_YRS "The checksum is used to check whether the data from the CPU buffer are shifted without transmission errors to the CAN communication controller buffer and vice versa.";
CM_ SG_ 308 YawRate "This signal indicates the yaw rate data (offset value; sign depends on mounting position)
anticlockwise=positive, clockwise=negative";
CM_ SG_ 308 YRSSt "This signal indicates the status of yaw rate sensor";
CM_ SG_ 308 Acceleration_X "The signal is LongitudinalAcceleration(compensated value).Positive value represents  forward,  negative value represents backward. ";
CM_ SG_ 308 Acceleration_Y "The signal is Lateral Acceleration(compensated value).Positive value represents right side of vehicle, negative value represents  left side of vehicle. ";
CM_ SG_ 308 ErrorSt_YRS "This signal indicates if the YRS is error or not.";
CM_ SG_ 308 LiveCounter_PDCM_YRS "The Livecounter is used to check the signal consistency of the messages . If the signals are consecutive, the LiveCounter should also be sequential in the way 0, 1, 2 ...X(depends on E2E usage), 0, 1 °≠";
CM_ SG_ 190 Checksum_RVA_1 "The checksum is used to check whether the data from the CPU buffer are shifted without transmission errors to the CAN communication controller buffer and vice versa.";
CM_ SG_ 190 SteerRearControlAngleReq_RVA "Target angle request from Master Controller";
CM_ SG_ 190 SteerRearControlSt_RVA "Control status for angle request, corporate with steer angle request to realize rear axle angle control";
CM_ SG_ 190 WorkingSt_RVA "This signal indicates the working status of RVA";
CM_ SG_ 190 BehaviorMode_RVA "This signal indicates the behavior mode of RVA";
CM_ SG_ 190 ErrorSt_RVA "This signal indicates the error status of RVA";
CM_ SG_ 190 IBCControlAvailable_RVA "Indicates IBC Control RWS is available or not.";
CM_ SG_ 190 APAControlSt_RVA "Indicates APA Control Request Feedback";
CM_ SG_ 190 APAAbortFeedback_RVA "This signal indicates APA Abort Feedback";
CM_ SG_ 190 SACCControlSt_RVA "This signal indicates the status of SACC Control SteerRearAngle";
CM_ SG_ 190 LKAControlSt_RVA "This signal indicates the status of LKA Control SteerRearAngle";
CM_ SG_ 190 NOPControlSt_RVA "This signal indicates the status of NOP Control SteerRearAngle";
CM_ SG_ 190 Livecounter_RVA_1 "The Livecounter is used to check the signal consistency of the messages . If the signals are consecutive, the LiveCounter should also be sequential in the way 0, 1, 2 °≠X(depends on E2E usage), 0, 1 °≠";
CM_ SG_ 190 SECOC_FV_RVA_1 "Fresh value signal for SECOC. The signal shall be proceeded following the byte order requirement in FAW-CYS-0033, i.e. SECOC spec";
CM_ SG_ 190 SECOC_TMAC_RVA_1 "Truncated MAC signal for SECOC. The signal shall be proceeded following the byte order requirement in FAW-CYS-0033, i.e. SECOC spec";
CM_ SG_ 686 TBOXTime_Hour "Indicates the TBOX system hour sent by TBOX(ICC).";
CM_ SG_ 686 TBOXTime_Minute "Indicates the TBOX system minute  sent by TBOX(ICC).";
CM_ SG_ 686 TBOXTime_Second "Indicates the TBOX system second sent by TBOX(ICC).";
CM_ SG_ 686 TBOXTime_Year "Indicates the TBOX system year sent by TBOX(ICC).";
CM_ SG_ 686 TBOXTime_Month "Indicates the TBOX system month sent by TBOX(ICC).";
CM_ SG_ 686 TBOXTime_Day "Indicates the TBOX system day sent by TBOX(ICC).";
CM_ SG_ 686 TBOXTime_Millisecond "Indicates the TBOX system millisecond sent by TBOX(ICC).";
CM_ SG_ 1376 SECOC_TripCounter "Trip counter value. The signal shall be procceded following the byte order requirement in FAW-CYS-0033, i.e. SECOC spec";
CM_ SG_ 1376 SECOC_ResetCounter "Reset counter value. The signal shall be procceded following the byte order requirement in FAW-CYS-0033, i.e. SECOC spec";
CM_ SG_ 1376 SECOC_Authenticator "CMAC value. The signal shall be procceded  following the  byte order requirement in FAW-CYS-0033, i.e. SECOC spec";
CM_ SG_ 280 Checksum_VDC_1 "The checksum is used to check whether the data from the CPU buffer are shifted without transmission errors to the CAN communication controller buffer and vice versa.";
CM_ SG_ 280 VDC_AutoDrivingReq_L12 "This signal indicates the acceleration or deceleration command is from L1L2 function £®SACC£©.
1. L12: Request assisted driving control, any related failure will deactivate the longitudinal controller.

";
CM_ SG_ 280 VDC_DecelerationReqEnable_AEB "This signal indicates the deceleration command  from AEB function.


";
CM_ SG_ 280 VDC_SteeringTorqueRequestSign "This signal Indicates sign of EMA steering torque";
CM_ SG_ 280 VDC_SteeringTorqueReqSt "This signal indicates the status of the steering torque request from EMA
";
CM_ SG_ 280 VDC_Intervention_LKA "This signal Indicates the LKA is Intervention or not";
CM_ SG_ 280 VDC_WorkingSt_LKA "This signal indicates the LKA working status.";
CM_ SG_ 280 VDC_ErrorSt_LKA "This signal indicates the LKA error status.";
CM_ SG_ 280 VDC_AccelerationPedalOverride "This signal indicates the torque demanded by the driver is higher than the torque demanded by ACC.";
CM_ SG_ 280 VDC_WorkingSt_AEB_L12 "This signal indicates the AEB working status.";
CM_ SG_ 280 VDC_ErrorSt_AEB_L12 "This signal indicates the AEB error status.";
CM_ SG_ 280 VDC_ErrorSt_ACC_L12 "This signal indicates the ACC error status.";
CM_ SG_ 280 VDC_SpeedChangeRequest_L12 "This signal is the value of acceleration request or deceleration request(SACC).";
CM_ SG_ 280 VDC_DriveAwayReq_L12 "This signal indicates VDC controller request vehicle drive off, ";
CM_ SG_ 280 VDC_StopReq_L12 "This signal indicates VDC controller request vehicle decelerate to standtill,";
CM_ SG_ 280 VDC_WorkingSt_ACC_L12 "This signal indicates the ACC working status.";
CM_ SG_ 280 VDC_TakeOverTip_LCA "This Driver should take over the vehicle.";
CM_ SG_ 280 VDC_ABPReq_L12 "This signal indicates the request for prefill function.";
CM_ SG_ 280 VDC_AWBReq_L12 "This signal in the request of the brake jerk warning to ESC.";
CM_ SG_ 280 VDC_AWBlevel_L12 "This signal indicates the different level request of the brake jerk warning.";
CM_ SG_ 280 VDC_CruiseModeFunctionInd "This signal indicates setting result of the configuration of cruise mode function.";
CM_ SG_ 280 VDC_BrakeModeReq_L12 "This signal indicate VDC request to brake cosily or urgently.
This signal is only used for L12 function";
CM_ SG_ 280 VDC_DrivedownModeReq_L12 "VDC request to quit out the auto pilot function.
This signal is only used for L12 function";
CM_ SG_ 280 VDC_SecureRequest_L12 "VDC request to stop the car safely.
This signal is only used for L12 function";
CM_ SG_ 280 VDC_AEBSensitivity_L12 "This signal indicates the sensitivity of AEB function";
CM_ SG_ 280 VDC_ErrorSt_LCA "This signal indicates the LCA error status.";
CM_ SG_ 280 VDC_AutoDrivingReq "Auto driving function active request from VDC to HCU.
";
CM_ SG_ 280 VDC_AutoDrivingLevel "This signal indicates the auto driving level of this car for auto driving data record.";
CM_ SG_ 280 VDC_HandsOffTip_LCA "Hands off, put hands on the steering wheel to active LCA function";
CM_ SG_ 280 VDC_ErrorSt_SACC "VDC system capbility for SACC";
CM_ SG_ 280 VDC_DecelerationReq_AEB "This signal is the value of  deceleration request(AEB).";
CM_ SG_ 280 VDC_WorkingSt_LCA "This signal indicates the LCA working status.";
CM_ SG_ 280 VDC_LDWSteeringVibrationReq "This signal indicates the request the steering vibration function. ";
CM_ SG_ 280 VDC_ErrorSt_VDC "This signal indicates VDC is error or not.If the value of this signal is °∞Error°Æ,EPS shoud ignore this message and respond the message from VDC.";
CM_ SG_ 280 VDC_SteeringTorqueRequest "This signal is the request steering wheel torque by EMA.in case of No Request: TorqueRequest_EMA = 0x3FE";
CM_ SG_ 280 VDC_AutoDrivingModeReq "This signal is the Source of Angle request to EPS.(LKA,SACC,L3Backup)
";
CM_ SG_ 280 VDC_WorkingSt_SACC "This signal indicates the SACC working status.";
CM_ SG_ 280 VDC_WorkingSt_DCLC "This signal indicates the DCLC working status.";
CM_ SG_ 280 VDC_ErrorSt_EMA "VDC system capbility for EMA.";
CM_ SG_ 280 VDC_WorkingSt_EMA "This signal indicates the EMA working status.";
CM_ SG_ 280 VDC_SteeringWheelAngleRequest "Steering Wheel Angle Request.(LKA,SACC,L3Backup)";
CM_ SG_ 280 SACC_RearWheelAngleRequestSt "This signal indicates the request status of SACC";
CM_ SG_ 280 VDC_SteeringWheelAngleSignReques "Steering Wheel Angle Sign Request..(LKA,SACC,L3Backup)";
CM_ SG_ 280 VDC_SteeringWheelAngleControlReq "Steering Wheel Angle Control Request..(LKA,SACC,L3Backup)";
CM_ SG_ 280 SACC_RearWheelReturnReq "This signal indicates the return to 0 request status of SACC";
CM_ SG_ 280 LKA_RearWheelAngleRequestSt "This signal indicates the request status of LKA";
CM_ SG_ 280 LKA_RearWheelReturnReq "This signal indicates the return to 0 request status of LKA";
CM_ SG_ 280 VDC_AutoDrivingModeReq_EMA "This signal is the Source of Torque request to EPS.(EMA)";
CM_ SG_ 280 VDC_SteeringWheelBlendingGain "Blending Gain Factor";
CM_ SG_ 280 VDC_SteeringMaxTorqueRequest "This signal indicates SACC/LKA request Max steering wheel torque .in case of Override ";
CM_ SG_ 280 SACC_RearWheelAngleRequest "This signal indicates the absolute value of SACC rear wheel angle request";
CM_ SG_ 280 LKA_RearWheelAngleRequest "This signal indicates the absolute value of LKA rear wheel angle request";
CM_ SG_ 280 VDC_WorkingSt_FCW "This signal indicates the FCW system working status.";
CM_ SG_ 280 VDC_ErrorSt_FCW "This signal indicates the FCW error status.";
CM_ SG_ 280 VDC_ErrorSt_L3Backup "VDC system capbility for L3Backup";
CM_ SG_ 280 VDC_WorkingSt_L3Backup "This signal indicates the L3Backup working status.";
CM_ SG_ 280 LiveCounter_VDC_1 "The Livecounter is used to check the signal consistency of the messages . If the signals are consecutive, the LiveCounter should also be sequential in the way 0, 1, 2 ...X(depends on E2E usage), 0, 1 °≠";
BA_DEF_ BO_  "VFrameFormat" ENUM  "StandardCAN","ExtendedCAN","reserved","reserved","reserved","reserved","reserved","reserved","reserved","reserved","reserved","reserved","reserved","reserved","StandardCAN_FD","ExtendedCAN_FD";
BA_DEF_  "ProtocolType" STRING ;
BA_DEF_ BU_  "NmAsrCanMsgReducedTime" INT 0 65535;
BA_DEF_ BO_  "GenMsgILSupport" ENUM  "No","Yes";
BA_DEF_ BO_  "CanTpSTmin" INT 0 0;
BA_DEF_ BO_  "CanTpFcFrameId" HEX 0 2147483647;
BA_DEF_  "NmAsrBaseAddress" HEX 0 2047;
BA_DEF_  "NmAsrMessageCount" INT 1 256;
BA_DEF_  "NmType" STRING ;
BA_DEF_  "Baudrate" INT 0 1000000;
BA_DEF_  "Manufacturer" STRING ;
BA_DEF_  "NmAsrWaitBusSleepTime" INT 0 65535;
BA_DEF_  "NmAsrTimeoutTime" INT 0 65535;
BA_DEF_  "NmAsrRepeatMessageTime" INT 0 65535;
BA_DEF_  "NmAsrCanMsgCycleTime" INT 0 65535;
BA_DEF_  "BusType" STRING ;
BA_DEF_  "DBName" STRING ;
BA_DEF_  "VersionNumber" INT 0 0;
BA_DEF_  "VersionDay" INT 0 31;
BA_DEF_  "VersionMonth" INT 0 12;
BA_DEF_  "VersionYear" INT 0 99;
BA_DEF_ BO_  "GenMsgSendType" ENUM  "Cyclic","not_used","not_used","not_used","not_used","Cyclic","not_used","IfActive","NoMsgSendType","Spontaneous","CyclicAndSpontaneous","NoMsgSendType";
BA_DEF_ BO_  "GenMsgCycleTime" INT 0 0;
BA_DEF_ SG_  "GenSigSendType" ENUM  "Cyclic","OnWrite","OnWriteWithRepetition","OnChange","OnChangeWithRepetition","IfActive","IfActiveWithRepetition","NoSigSendType";
BA_DEF_ SG_  "GenSigStartValue" INT 0 0;
BA_DEF_ SG_  "GenSigInvalidValue" INT 0 0;
BA_DEF_ SG_  "GenSigStartRemark" STRING ;
BA_DEF_ SG_  "GenSigInvalidRemark" STRING ;
BA_DEF_ SG_  "GenSigEvent" STRING ;
BA_DEF_ SG_  "SystemSignalLongSymbol" STRING ;
BA_DEF_REL_ BU_SG_REL_  "GenSigTimeoutTime" INT 0 5000;
BA_DEF_DEF_  "VFrameFormat" "ExtendedCAN_FD";
BA_DEF_DEF_  "ProtocolType" "*";
BA_DEF_DEF_  "NmAsrCanMsgReducedTime" 50;
BA_DEF_DEF_  "GenMsgILSupport" "Yes";
BA_DEF_DEF_  "CanTpSTmin" 1;
BA_DEF_DEF_  "CanTpFcFrameId" 2147483647;
BA_DEF_DEF_  "NmAsrBaseAddress" 1280;
BA_DEF_DEF_  "NmAsrMessageCount" 128;
BA_DEF_DEF_  "NmType" "NmAsr";
BA_DEF_DEF_  "Baudrate" 500000;
BA_DEF_DEF_  "Manufacturer" "FAW";
BA_DEF_DEF_  "NmAsrWaitBusSleepTime" 750;
BA_DEF_DEF_  "NmAsrTimeoutTime" 1000;
BA_DEF_DEF_  "NmAsrRepeatMessageTime" 400;
BA_DEF_DEF_  "NmAsrCanMsgCycleTime" 100;
BA_DEF_DEF_  "BusType" "CAN";
BA_DEF_DEF_REL_ "GenSigTimeoutTime" 0;
BA_DEF_DEF_  "DBName" "";
BA_DEF_DEF_  "VersionNumber" 0;
BA_DEF_DEF_  "VersionDay" 1;
BA_DEF_DEF_  "VersionMonth" 1;
BA_DEF_DEF_  "VersionYear" 0;
BA_DEF_DEF_  "GenMsgSendType" "Cyclic";
BA_DEF_DEF_  "GenMsgCycleTime" 0;
BA_DEF_DEF_  "GenSigSendType" "NoSigSendType";
BA_DEF_DEF_  "GenSigStartValue" 0;
BA_DEF_DEF_  "GenSigInvalidValue" 0;
BA_DEF_DEF_  "GenSigStartRemark" "";
BA_DEF_DEF_  "GenSigInvalidRemark" "";
BA_DEF_DEF_  "GenSigEvent" "";
BA_DEF_DEF_  "SystemSignalLongSymbol" "";
BA_ "BusType" "CAN FD";
BA_ "VersionYear" 23;
BA_ "VersionDay" 12;
BA_ "VersionNumber" 0.9;
BA_ "DBName" "FAW_E001F_CHS1Front_Gateway_CAND";
BA_ "GenMsgCycleTime" BO_ 256 20;
BA_ "VFrameFormat" BO_ 256 14;
BA_ "GenMsgCycleTime" BO_ 546 100;
BA_ "VFrameFormat" BO_ 546 14;
BA_ "GenMsgCycleTime" BO_ 586 100;
BA_ "VFrameFormat" BO_ 586 14;
BA_ "GenMsgCycleTime" BO_ 532 100;
BA_ "VFrameFormat" BO_ 532 14;
BA_ "GenMsgCycleTime" BO_ 580 100;
BA_ "VFrameFormat" BO_ 580 14;
BA_ "GenMsgCycleTime" BO_ 233 10;
BA_ "VFrameFormat" BO_ 233 14;
BA_ "GenMsgCycleTime" BO_ 206 10;
BA_ "VFrameFormat" BO_ 206 14;
BA_ "GenMsgCycleTime" BO_ 282 20;
BA_ "VFrameFormat" BO_ 282 14;
BA_ "GenMsgCycleTime" BO_ 151 10;
BA_ "VFrameFormat" BO_ 151 14;
BA_ "GenMsgCycleTime" BO_ 290 20;
BA_ "VFrameFormat" BO_ 290 14;
BA_ "GenMsgCycleTime" BO_ 146 10;
BA_ "VFrameFormat" BO_ 146 14;
BA_ "GenMsgCycleTime" BO_ 264 10;
BA_ "VFrameFormat" BO_ 264 14;
BA_ "GenMsgCycleTime" BO_ 147 10;
BA_ "VFrameFormat" BO_ 147 14;
BA_ "GenMsgCycleTime" BO_ 640 100;
BA_ "VFrameFormat" BO_ 640 14;
BA_ "GenMsgCycleTime" BO_ 670 100;
BA_ "VFrameFormat" BO_ 670 14;
BA_ "GenMsgCycleTime" BO_ 656 100;
BA_ "VFrameFormat" BO_ 656 14;
BA_ "GenMsgCycleTime" BO_ 308 20;
BA_ "VFrameFormat" BO_ 308 14;
BA_ "GenMsgCycleTime" BO_ 190 10;
BA_ "VFrameFormat" BO_ 190 14;
BA_ "GenMsgCycleTime" BO_ 686 100;
BA_ "VFrameFormat" BO_ 686 14;
BA_ "GenMsgCycleTime" BO_ 1376 30000;
BA_ "VFrameFormat" BO_ 1376 14;
BA_ "GenMsgCycleTime" BO_ 280 20;
BA_ "VFrameFormat" BO_ 280 14;
BA_ "GenSigStartRemark" SG_ 256 Checksum_ADV_2 "V";
BA_ "GenSigStartRemark" SG_ 256 ADV_WorkingSt_APA "L";
BA_ "GenSigStartRemark" SG_ 256 ADV_WorkingSt_RPA "L";
BA_ "GenSigStartRemark" SG_ 256 ADV_WorkingSt_AVP "L";
BA_ "GenSigInvalidRemark" SG_ 256 ADV_SteeringWheelAngleRequest "O";
BA_ "GenSigInvalidValue" SG_ 256 ADV_SteeringWheelAngleRequest 32767;
BA_ "SystemSignalLongSymbol" SG_ 256 ADV_SteeringWheelAngleSignReques "ADV_SteeringWheelAngleSignRequest";
BA_ "SystemSignalLongSymbol" SG_ 256 ADV_SteeringWheelAngleControlReq "ADV_SteeringWheelAngleControlRequest";
BA_ "GenSigInvalidValue" SG_ 256 ADV_RearWheelAngleRequest 4095;
BA_ "GenSigStartValue" SG_ 256 ADV_RearWheelAngleRequest 4094;
BA_ "GenSigInvalidValue" SG_ 256 APA_FailureBrakeMode 7;
BA_ "GenSigInvalidRemark" SG_ 546 AmbientTemp "O";
BA_ "GenSigStartRemark" SG_ 546 AmbientTemp "O";
BA_ "GenSigInvalidValue" SG_ 546 AmbientTemp 255;
BA_ "GenSigStartValue" SG_ 546 AmbientTemp 254;
BA_ "GenSigEvent" SG_ 532 DMS_ESCModeChangeCmd "Y";
BA_ "GenSigSendType" SG_ 532 DMS_ESCModeChangeCmd 1;
BA_ "GenSigStartValue" SG_ 532 DMS_ESCModeChangeCmd 1;
BA_ "GenSigEvent" SG_ 532 DMS_EPSModeChangeCmd "Y";
BA_ "GenSigSendType" SG_ 532 DMS_EPSModeChangeCmd 1;
BA_ "GenSigInvalidValue" SG_ 580 FLSeatBackAngle 31;
BA_ "GenSigStartValue" SG_ 580 FLSeatBackAngle 30;
BA_ "SystemSignalLongSymbol" SG_ 233 PbcInDriveAwayIntentionIndicatio "PbcInDriveAwayIntentionIndication_M";
BA_ "SystemSignalLongSymbol" SG_ 233 PbcRollerbenchApplyControlState_ "PbcRollerbenchApplyControlState_M";
BA_ "GenSigStartRemark" SG_ 206 Checksum_EPBMaster_1 "V";
BA_ "SystemSignalLongSymbol" SG_ 206 BrakeForceNotEnoughWarning_EPBMa "BrakeForceNotEnoughWarning_EPBMaster";
BA_ "GenSigInvalidRemark" SG_ 206 EPBMasterDecelerationRequest "O";
BA_ "GenSigStartRemark" SG_ 206 EPBMasterDecelerationRequest "O";
BA_ "GenSigInvalidValue" SG_ 206 EPBMasterDecelerationRequest 4095;
BA_ "GenSigStartValue" SG_ 206 EPBMasterDecelerationRequest 4094;
BA_ "SystemSignalLongSymbol" SG_ 206 StatusEPBMasterDecelerationReque "StatusEPBMasterDecelerationRequest";
BA_ "GenSigStartRemark" SG_ 282 Checksum_HAD_3 "V";
BA_ "GenSigInvalidValue" SG_ 282 HAD_SpeedChangeRequest_L3 2047;
BA_ "GenSigStartValue" SG_ 282 HAD_SpeedChangeRequest_L3 2046;
BA_ "GenSigEvent" SG_ 282 HAD_TimeGapSetting "Y";
BA_ "GenSigSendType" SG_ 282 HAD_TimeGapSetting 1;
BA_ "GenSigStartValue" SG_ 282 HAD_TimeGapSetting 3;
BA_ "GenSigInvalidValue" SG_ 282 NOP_RearWheelAngleRequest 4095;
BA_ "GenSigStartValue" SG_ 282 NOP_RearWheelAngleRequest 4094;
BA_ "GenSigEvent" SG_ 282 HAD_TakeOverReq "Y";
BA_ "GenSigSendType" SG_ 282 HAD_TakeOverReq 1;
BA_ "GenSigInvalidRemark" SG_ 282 HAD_CruiseSpeedSetting_ACC "O";
BA_ "GenSigStartRemark" SG_ 282 HAD_CruiseSpeedSetting_ACC "O";
BA_ "GenSigInvalidValue" SG_ 282 HAD_CruiseSpeedSetting_ACC 255;
BA_ "GenSigStartValue" SG_ 282 HAD_CruiseSpeedSetting_ACC 254;
BA_ "GenSigStartRemark" SG_ 282 HAD_LDWModeInd "L";
BA_ "GenSigEvent" SG_ 282 HAD_AutoLightModeReq "Y";
BA_ "GenSigSendType" SG_ 282 HAD_AutoLightModeReq 1;
BA_ "GenSigEvent" SG_ 282 HAD_HazardWarningLampRequest "Y";
BA_ "GenSigSendType" SG_ 282 HAD_HazardWarningLampRequest 1;
BA_ "GenSigStartValue" SG_ 282 HAD_WorkingSt_LDW 1;
BA_ "GenSigEvent" SG_ 282 HAD_WarningCmd_LDW "Y";
BA_ "GenSigSendType" SG_ 282 HAD_WarningCmd_LDW 1;
BA_ "GenSigStartRemark" SG_ 282 HAD_SensitivityInd_LDW "L";
BA_ "GenSigStartValue" SG_ 282 HAD_WorkingSt_FCW 1;
BA_ "GenSigStartRemark" SG_ 282 HAD_SensitivityInd_FCW "L";
BA_ "GenSigStartValue" SG_ 282 HAD_FCWModeInd 1;
BA_ "GenSigEvent" SG_ 282 HAD_LDW_SpeechControlFeedback "Y";
BA_ "GenSigSendType" SG_ 282 HAD_LDW_SpeechControlFeedback 1;
BA_ "GenSigStartRemark" SG_ 282 HAD_ValetModeStatus "L";
BA_ "GenSigStartRemark" SG_ 282 HAD_WorkingSt_NOP "L";
BA_ "GenSigInvalidValue" SG_ 282 HAD_SteeringWheelBlendingGain 255;
BA_ "GenSigInvalidRemark" SG_ 282 HAD_SteeringWheelAngleRequest "O";
BA_ "GenSigInvalidValue" SG_ 282 HAD_SteeringWheelAngleRequest 32767;
BA_ "SystemSignalLongSymbol" SG_ 282 HAD_SteeringWheelAngleSignReques "HAD_SteeringWheelAngleSignRequest";
BA_ "SystemSignalLongSymbol" SG_ 282 HAD_SteeringWheelAngleControlReq "HAD_SteeringWheelAngleControlRequest";
BA_ "GenSigStartRemark" SG_ 282 HAD_WorkingSt_NGP "L";
BA_ "GenSigStartRemark" SG_ 151 Checksum_HCU_2_10 "V";
BA_ "GenSigInvalidValue" SG_ 151 HCU_MCU1TMSpeed 65535;
BA_ "GenSigStartValue" SG_ 151 HCU_MCU1TMSpeed 65534;
BA_ "GenSigInvalidValue" SG_ 151 HCU_FrontWheelActTorque 16383;
BA_ "GenSigStartValue" SG_ 151 HCU_FrontWheelActTorque 16382;
BA_ "GenSigInvalidValue" SG_ 151 HCU_FrontWheelMaxDriveTorque 8191;
BA_ "GenSigStartValue" SG_ 151 HCU_FrontWheelMaxDriveTorque 8190;
BA_ "GenSigInvalidValue" SG_ 151 HCU_FrontWheelMaxBrakeRegTorque 8191;
BA_ "GenSigStartValue" SG_ 151 HCU_FrontWheelMaxBrakeRegTorque 8190;
BA_ "GenSigInvalidValue" SG_ 151 HCU_FrontWheelBrakeRegTorque 8191;
BA_ "GenSigStartValue" SG_ 151 HCU_FrontWheelBrakeRegTorque 8190;
BA_ "GenSigInvalidValue" SG_ 151 HCU_MCU2TMSpeed 65535;
BA_ "GenSigStartValue" SG_ 151 HCU_MCU2TMSpeed 65534;
BA_ "GenSigInvalidValue" SG_ 151 HCU_RearWheelActTorque 16383;
BA_ "GenSigStartValue" SG_ 151 HCU_RearWheelActTorque 16382;
BA_ "GenSigInvalidValue" SG_ 151 HCU_RearWheelMaxDriveTorque 8191;
BA_ "GenSigStartValue" SG_ 151 HCU_RearWheelMaxDriveTorque 8190;
BA_ "GenSigInvalidValue" SG_ 151 HCU_RearWheelMaxBrakeRegTorque 8191;
BA_ "GenSigStartValue" SG_ 151 HCU_RearWheelMaxBrakeRegTorque 8190;
BA_ "GenSigInvalidValue" SG_ 151 HCU_RearWheelBrakeRegTorque 8191;
BA_ "GenSigStartValue" SG_ 151 HCU_RearWheelBrakeRegTorque 8190;
BA_ "GenSigStartRemark" SG_ 290 Checksum_HCU_2_12 "V";
BA_ "GenSigInvalidValue" SG_ 290 HCU2_LeverInfo 7;
BA_ "GenSigStartValue" SG_ 290 HCU2_LeverInfo 5;
BA_ "GenSigStartRemark" SG_ 146 Checksum_HCU_2_2 "V";
BA_ "GenSigInvalidValue" SG_ 146 HCU_EPBLeverRequest 7;
BA_ "GenSigInvalidValue" SG_ 146 HCU_AccelerationPedalPosition 255;
BA_ "GenSigStartValue" SG_ 146 HCU_AccelerationPedalPosition 254;
BA_ "GenSigInvalidValue" SG_ 146 HCU_CalcAccelerationPedalPositio 255;
BA_ "GenSigStartValue" SG_ 146 HCU_CalcAccelerationPedalPositio 254;
BA_ "SystemSignalLongSymbol" SG_ 146 HCU_CalcAccelerationPedalPositio "HCU_CalcAccelerationPedalPosition";
BA_ "GenSigInvalidValue" SG_ 146 LiveCounter_HCU_2_2 15;
BA_ "GenSigStartRemark" SG_ 264 Checksum_HCU_2_4 "V";
BA_ "GenSigInvalidValue" SG_ 264 HCU_DriverTorq_FrontWheel 65535;
BA_ "GenSigStartValue" SG_ 264 HCU_DriverTorq_FrontWheel 65534;
BA_ "GenSigInvalidValue" SG_ 264 HCU_CruiseControlSt 3;
BA_ "GenSigInvalidValue" SG_ 264 HCU_DriverTorq_RearWheel 65535;
BA_ "GenSigStartValue" SG_ 264 HCU_DriverTorq_RearWheel 65534;
BA_ "GenSigInvalidRemark" SG_ 264 HCU_GradientAccelerationPedal "O";
BA_ "GenSigStartRemark" SG_ 264 HCU_GradientAccelerationPedal "O";
BA_ "GenSigInvalidValue" SG_ 264 HCU_GradientAccelerationPedal 255;
BA_ "GenSigStartValue" SG_ 264 HCU_GradientAccelerationPedal 254;
BA_ "GenSigStartRemark" SG_ 147 Checksum_HCU_2_7 "V";
BA_ "SystemSignalLongSymbol" SG_ 147 HCU_SlipContrlIntervention_Front "HCU_SlipContrlIntervention_FrontAxle";
BA_ "SystemSignalLongSymbol" SG_ 147 HCU_SlipContrlIntervention_RearA "HCU_SlipContrlIntervention_RearAxle";
BA_ "GenSigStartRemark" SG_ 640 Checksum_HU_1 "V";
BA_ "GenSigEvent" SG_ 640 EPBAutoLockFunctionReq "Y";
BA_ "GenSigSendType" SG_ 640 EPBAutoLockFunctionReq 1;
BA_ "GenSigEvent" SG_ 640 ESCFunctionReq "Y";
BA_ "GenSigSendType" SG_ 640 ESCFunctionReq 1;
BA_ "GenSigEvent" SG_ 640 HDCFunctionReq "Y";
BA_ "GenSigSendType" SG_ 640 HDCFunctionReq 1;
BA_ "GenSigEvent" SG_ 640 CSTFunctionReq "Y";
BA_ "GenSigSendType" SG_ 640 CSTFunctionReq 1;
BA_ "GenSigStartRemark" SG_ 670 Checksum_HU_16 "V";
BA_ "GenSigEvent" SG_ 670 HU_AVHFunctionReq "Y";
BA_ "GenSigSendType" SG_ 670 HU_AVHFunctionReq 1;
BA_ "GenSigInvalidRemark" SG_ 656 OdometerValue "O";
BA_ "GenSigStartRemark" SG_ 656 OdometerValue "L";
BA_ "GenSigInvalidValue" SG_ 656 OdometerValue 33554431;
BA_ "GenSigStartRemark" SG_ 308 Checksum_PDCM_YRS "V";
BA_ "GenSigInvalidValue" SG_ 308 YawRate 4095;
BA_ "GenSigStartValue" SG_ 308 YawRate 4094;
BA_ "GenSigInvalidValue" SG_ 308 Acceleration_X 2047;
BA_ "GenSigStartValue" SG_ 308 Acceleration_X 2046;
BA_ "GenSigInvalidValue" SG_ 308 Acceleration_Y 2047;
BA_ "GenSigStartValue" SG_ 308 Acceleration_Y 2046;
BA_ "GenSigStartRemark" SG_ 190 Checksum_RVA_1 "V";
BA_ "GenSigInvalidValue" SG_ 190 SteerRearControlAngleReq_RVA 4095;
BA_ "GenSigStartValue" SG_ 190 SteerRearControlAngleReq_RVA 4094;
BA_ "GenSigInvalidValue" SG_ 686 TBOXTime_Hour 31;
BA_ "GenSigStartValue" SG_ 686 TBOXTime_Hour 30;
BA_ "GenSigInvalidValue" SG_ 686 TBOXTime_Minute 63;
BA_ "GenSigStartValue" SG_ 686 TBOXTime_Minute 62;
BA_ "GenSigInvalidValue" SG_ 686 TBOXTime_Second 63;
BA_ "GenSigStartValue" SG_ 686 TBOXTime_Second 62;
BA_ "GenSigInvalidRemark" SG_ 686 TBOXTime_Year "O";
BA_ "GenSigStartRemark" SG_ 686 TBOXTime_Year "O";
BA_ "GenSigInvalidValue" SG_ 686 TBOXTime_Year 127;
BA_ "GenSigStartValue" SG_ 686 TBOXTime_Year 126;
BA_ "GenSigInvalidValue" SG_ 686 TBOXTime_Month 15;
BA_ "GenSigStartValue" SG_ 686 TBOXTime_Month 14;
BA_ "GenSigInvalidValue" SG_ 686 TBOXTime_Day 127;
BA_ "GenSigStartValue" SG_ 686 TBOXTime_Day 126;
BA_ "GenSigInvalidValue" SG_ 686 TBOXTime_Millisecond 1023;
BA_ "GenSigStartValue" SG_ 686 TBOXTime_Millisecond 1022;
BA_ "GenSigStartRemark" SG_ 280 Checksum_VDC_1 "V";
BA_ "GenSigStartRemark" SG_ 280 VDC_WorkingSt_LKA "L";
BA_ "GenSigStartValue" SG_ 280 VDC_WorkingSt_AEB_L12 1;
BA_ "GenSigInvalidValue" SG_ 280 VDC_SpeedChangeRequest_L12 2047;
BA_ "GenSigStartValue" SG_ 280 VDC_SpeedChangeRequest_L12 2046;
BA_ "GenSigStartRemark" SG_ 280 VDC_CruiseModeFunctionInd "L";
BA_ "GenSigInvalidRemark" SG_ 280 VDC_DecelerationReq_AEB "O";
BA_ "GenSigStartRemark" SG_ 280 VDC_DecelerationReq_AEB "O";
BA_ "GenSigInvalidValue" SG_ 280 VDC_DecelerationReq_AEB 1023;
BA_ "GenSigStartValue" SG_ 280 VDC_DecelerationReq_AEB 1022;
BA_ "GenSigStartRemark" SG_ 280 VDC_WorkingSt_LCA "L";
BA_ "GenSigEvent" SG_ 280 VDC_LDWSteeringVibrationReq "Y";
BA_ "GenSigSendType" SG_ 280 VDC_LDWSteeringVibrationReq 1;
BA_ "GenSigInvalidValue" SG_ 280 VDC_SteeringTorqueRequest 1023;
BA_ "GenSigStartValue" SG_ 280 VDC_SteeringTorqueRequest 1022;
BA_ "GenSigStartRemark" SG_ 280 VDC_WorkingSt_SACC "L";
BA_ "GenSigStartRemark" SG_ 280 VDC_WorkingSt_DCLC "L";
BA_ "GenSigStartRemark" SG_ 280 VDC_WorkingSt_EMA "L";
BA_ "GenSigInvalidRemark" SG_ 280 VDC_SteeringWheelAngleRequest "O";
BA_ "GenSigInvalidValue" SG_ 280 VDC_SteeringWheelAngleRequest 32767;
BA_ "SystemSignalLongSymbol" SG_ 280 VDC_SteeringWheelAngleSignReques "VDC_SteeringWheelAngleSignRequest";
BA_ "GenSigInvalidValue" SG_ 280 VDC_SteeringWheelBlendingGain 255;
BA_ "GenSigInvalidValue" SG_ 280 VDC_SteeringMaxTorqueRequest 1023;
BA_ "GenSigStartValue" SG_ 280 VDC_SteeringMaxTorqueRequest 1022;
BA_ "GenSigInvalidValue" SG_ 280 SACC_RearWheelAngleRequest 4095;
BA_ "GenSigStartValue" SG_ 280 SACC_RearWheelAngleRequest 4094;
BA_ "GenSigInvalidValue" SG_ 280 LKA_RearWheelAngleRequest 4095;
BA_ "GenSigStartValue" SG_ 280 LKA_RearWheelAngleRequest 4094;
BA_ "GenSigStartValue" SG_ 280 VDC_WorkingSt_FCW 1;
BA_ "GenSigStartRemark" SG_ 280 VDC_WorkingSt_L3Backup "L";
BA_REL_ "GenSigTimeoutTime" BU_SG_REL_ EPS SG_ 256 Checksum_ADV_2 200;
BA_REL_ "GenSigTimeoutTime" BU_SG_REL_ IBC SG_ 256 Checksum_ADV_2 200;
BA_REL_ "GenSigTimeoutTime" BU_SG_REL_ EPS SG_ 256 ADV_ErrorSt_EPS 200;
BA_REL_ "GenSigTimeoutTime" BU_SG_REL_ EPS SG_ 256 ADV_AutoParkingModeReq 200;
BA_REL_ "GenSigTimeoutTime" BU_SG_REL_ PDCR SG_ 256 ADV_AutoParkingModeReq 200;
BA_REL_ "GenSigTimeoutTime" BU_SG_REL_ EPS SG_ 256 ADV_AutoParkingRequestSt 200;
BA_REL_ "GenSigTimeoutTime" BU_SG_REL_ PDCR SG_ 256 ADV_AutoParkingRequestSt 200;
BA_REL_ "GenSigTimeoutTime" BU_SG_REL_ IBC SG_ 256 APA_DriverInterventionSt 200;
BA_REL_ "GenSigTimeoutTime" BU_SG_REL_ EPS SG_ 256 ADV_ErrorSt_APA 200;
BA_REL_ "GenSigTimeoutTime" BU_SG_REL_ EPS SG_ 256 ADV_ErrorSt_RPA 200;
BA_REL_ "GenSigTimeoutTime" BU_SG_REL_ EPS SG_ 256 ADV_ErrorSt_AVP 200;
BA_REL_ "GenSigTimeoutTime" BU_SG_REL_ EPS SG_ 256 ADV_WorkingSt_APA 200;
BA_REL_ "GenSigTimeoutTime" BU_SG_REL_ EPS SG_ 256 ADV_WorkingSt_RPA 200;
BA_REL_ "GenSigTimeoutTime" BU_SG_REL_ EPS SG_ 256 ADV_WorkingSt_AVP 200;
BA_REL_ "GenSigTimeoutTime" BU_SG_REL_ IBC SG_ 256 APA_SecureRequest 200;
BA_REL_ "GenSigTimeoutTime" BU_SG_REL_ IBC SG_ 256 APA_AutoParkingReq 200;
BA_REL_ "GenSigTimeoutTime" BU_SG_REL_ PDCR SG_ 256 APA_AutoParkingReq 200;
BA_REL_ "GenSigTimeoutTime" BU_SG_REL_ IBC SG_ 256 APA_DirectionCmd 200;
BA_REL_ "GenSigTimeoutTime" BU_SG_REL_ EPS SG_ 256 ADV_SteeringWheelAngleRequest 200;
BA_REL_ "GenSigTimeoutTime" BU_SG_REL_ EPS SG_ 256 ADV_SteeringWheelAngleSignReques 200;
BA_REL_ "GenSigTimeoutTime" BU_SG_REL_ EPS SG_ 256 ADV_SteeringWheelAngleControlReq 200;
BA_REL_ "GenSigTimeoutTime" BU_SG_REL_ IBC SG_ 256 APA_BrakeFunctionMode 200;
BA_REL_ "GenSigTimeoutTime" BU_SG_REL_ PDCR SG_ 256 APA_BrakeFunctionMode 200;
BA_REL_ "GenSigTimeoutTime" BU_SG_REL_ IBC SG_ 256 APA_StopDistance 200;
BA_REL_ "GenSigTimeoutTime" BU_SG_REL_ IBC SG_ 256 APA_SpeedLimitation 200;
BA_REL_ "GenSigTimeoutTime" BU_SG_REL_ IBC SG_ 256 APA_FailureBrakeMode 200;
BA_REL_ "GenSigTimeoutTime" BU_SG_REL_ EPS SG_ 256 LiveCounter_ADV_2 200;
BA_REL_ "GenSigTimeoutTime" BU_SG_REL_ IBC SG_ 256 LiveCounter_ADV_2 200;
BA_REL_ "GenSigTimeoutTime" BU_SG_REL_ IBC SG_ 256 SECOC_FV_ADV_2 200;
BA_REL_ "GenSigTimeoutTime" BU_SG_REL_ IBC SG_ 256 SECOC_TMAC_ADV_2 200;
BA_REL_ "GenSigTimeoutTime" BU_SG_REL_ IBC SG_ 546 AmbientTemp 1000;
BA_REL_ "GenSigTimeoutTime" BU_SG_REL_ IBC SG_ 586 DoorSt_FL 1000;
BA_REL_ "GenSigTimeoutTime" BU_SG_REL_ IBC SG_ 532 DMS_ESCModeChangeCmd 1000;
BA_REL_ "GenSigTimeoutTime" BU_SG_REL_ EPS SG_ 532 DMS_EPSModeChangeCmd 1000;
BA_REL_ "GenSigTimeoutTime" BU_SG_REL_ IBC SG_ 580 SeatBeltSt_DSCU 1000;
BA_REL_ "GenSigTimeoutTime" BU_SG_REL_ PDCR SG_ 233 PbcOutActuatorState_M 100;
BA_REL_ "GenSigTimeoutTime" BU_SG_REL_ PDCR SG_ 233 PbcOutPadAdjustmentRequest_M 100;
BA_REL_ "GenSigTimeoutTime" BU_SG_REL_ PDCR SG_ 233 PbcInHostAvailability_M 100;
BA_REL_ "GenSigTimeoutTime" BU_SG_REL_ PDCR SG_ 233 PbcInApplyReleaseRequest_M 100;
BA_REL_ "GenSigTimeoutTime" BU_SG_REL_ PDCR SG_ 233 PbcInRollerbenchActive_M 100;
BA_REL_ "GenSigTimeoutTime" BU_SG_REL_ PDCR SG_ 233 PbcInDriveAwayIntentionIndicatio 100;
BA_REL_ "GenSigTimeoutTime" BU_SG_REL_ PDCR SG_ 233 PbcEnableLineLock_M 100;
BA_REL_ "GenSigTimeoutTime" BU_SG_REL_ PDCR SG_ 233 PbcEnableLineRelease_M 100;
BA_REL_ "GenSigTimeoutTime" BU_SG_REL_ PDCR SG_ 233 EpbDegradedMode_M 100;
BA_REL_ "GenSigTimeoutTime" BU_SG_REL_ PDCR SG_ 233 PbcDynApplyControlState_M 100;
BA_REL_ "GenSigTimeoutTime" BU_SG_REL_ PDCR SG_ 233 PbcRollerbenchApplyControlState_ 100;
BA_REL_ "GenSigTimeoutTime" BU_SG_REL_ PDCR SG_ 233 IsRelTchPt_M 100;
BA_REL_ "GenSigTimeoutTime" BU_SG_REL_ PDCR SG_ 233 IsRWAAppEn_M 100;
BA_REL_ "GenSigTimeoutTime" BU_SG_REL_ PDCR SG_ 233 IsRWARelEn_M 100;
BA_REL_ "GenSigTimeoutTime" BU_SG_REL_ PDCR SG_ 233 RWACntrStpApp_M 100;
BA_REL_ "GenSigTimeoutTime" BU_SG_REL_ PDCR SG_ 233 CntrRWAAppHld_M 100;
BA_REL_ "GenSigTimeoutTime" BU_SG_REL_ PDCR SG_ 233 PbcRWAControlState_M 100;
BA_REL_ "GenSigTimeoutTime" BU_SG_REL_ IBC SG_ 206 Checksum_EPBMaster_1 100;
BA_REL_ "GenSigTimeoutTime" BU_SG_REL_ IBC SG_ 206 EPBMaster_Switch_1 100;
BA_REL_ "GenSigTimeoutTime" BU_SG_REL_ IBC SG_ 206 EPBMasterDecelerationRequest 100;
BA_REL_ "GenSigTimeoutTime" BU_SG_REL_ IBC SG_ 206 StatusEPBMasterDecelerationReque 100;
BA_REL_ "GenSigTimeoutTime" BU_SG_REL_ IBC SG_ 206 WorkingSt_EPBMaster_1 100;
BA_REL_ "GenSigTimeoutTime" BU_SG_REL_ RBU SG_ 206 WorkingSt_EPBMaster_1 100;
BA_REL_ "GenSigTimeoutTime" BU_SG_REL_ IBC SG_ 206 ErrorSt_EPBMaster_1 100;
BA_REL_ "GenSigTimeoutTime" BU_SG_REL_ IBC SG_ 206 LiveCounter_EPBMaster_1 100;
BA_REL_ "GenSigTimeoutTime" BU_SG_REL_ EPS SG_ 282 Checksum_HAD_3 200;
BA_REL_ "GenSigTimeoutTime" BU_SG_REL_ IBC SG_ 282 Checksum_HAD_3 200;
BA_REL_ "GenSigTimeoutTime" BU_SG_REL_ IBC SG_ 282 HAD_AutoDrivingReq_L3 200;
BA_REL_ "GenSigTimeoutTime" BU_SG_REL_ RBU SG_ 282 HAD_AutoDrivingReq_L3 200;
BA_REL_ "GenSigTimeoutTime" BU_SG_REL_ IBC SG_ 282 HAD_SpeedChangeRequest_L3 200;
BA_REL_ "GenSigTimeoutTime" BU_SG_REL_ RBU SG_ 282 HAD_SpeedChangeRequest_L3 200;
BA_REL_ "GenSigTimeoutTime" BU_SG_REL_ IBC SG_ 282 HAD_DriveAwayReq_L3 200;
BA_REL_ "GenSigTimeoutTime" BU_SG_REL_ IBC SG_ 282 HAD_StopReq_L3 200;
BA_REL_ "GenSigTimeoutTime" BU_SG_REL_ RBU SG_ 282 HAD_StopReq_L3 200;
BA_REL_ "GenSigTimeoutTime" BU_SG_REL_ IBC SG_ 282 HAD_AccelerationPedalOverride 200;
BA_REL_ "GenSigTimeoutTime" BU_SG_REL_ IBC SG_ 282 HAD_BrakeModeReq_L3 200;
BA_REL_ "GenSigTimeoutTime" BU_SG_REL_ RBU SG_ 282 HAD_BrakeModeReq_L3 200;
BA_REL_ "GenSigTimeoutTime" BU_SG_REL_ IBC SG_ 282 HAD_DrivedownModeReq_L3 200;
BA_REL_ "GenSigTimeoutTime" BU_SG_REL_ RBU SG_ 282 HAD_DrivedownModeReq_L3 200;
BA_REL_ "GenSigTimeoutTime" BU_SG_REL_ IBC SG_ 282 HAD_SecureRequest_L3 200;
BA_REL_ "GenSigTimeoutTime" BU_SG_REL_ RBU SG_ 282 HAD_SecureRequest_L3 200;
BA_REL_ "GenSigTimeoutTime" BU_SG_REL_ IBC SG_ 282 HAD_ErrorSt_AutoDriving_L3 200;
BA_REL_ "GenSigTimeoutTime" BU_SG_REL_ RBU SG_ 282 HAD_ErrorSt_AutoDriving_L3 200;
BA_REL_ "GenSigTimeoutTime" BU_SG_REL_ EPS SG_ 282 HAD_WorkingSt_NOP 200;
BA_REL_ "GenSigTimeoutTime" BU_SG_REL_ EPS SG_ 282 HAD_ErrorSt_NOP 200;
BA_REL_ "GenSigTimeoutTime" BU_SG_REL_ EPS SG_ 282 HAD_ErrorSt_HAD 200;
BA_REL_ "GenSigTimeoutTime" BU_SG_REL_ IBC SG_ 282 HAD_ErrorSt_HAD 200;
BA_REL_ "GenSigTimeoutTime" BU_SG_REL_ RBU SG_ 282 HAD_ErrorSt_HAD 200;
BA_REL_ "GenSigTimeoutTime" BU_SG_REL_ EPS SG_ 282 HAD_AutoDrivingModeReq_NOP 200;
BA_REL_ "GenSigTimeoutTime" BU_SG_REL_ EPS SG_ 282 HAD_AutoDrivingModeReq_NGP 200;
BA_REL_ "GenSigTimeoutTime" BU_SG_REL_ EPS SG_ 282 HAD_SteeringWheelBlendingGain 200;
BA_REL_ "GenSigTimeoutTime" BU_SG_REL_ EPS SG_ 282 HAD_SteeringWheelAngleRequest 200;
BA_REL_ "GenSigTimeoutTime" BU_SG_REL_ EPS SG_ 282 HAD_SteeringWheelAngleSignReques 200;
BA_REL_ "GenSigTimeoutTime" BU_SG_REL_ EPS SG_ 282 HAD_SteeringWheelAngleControlReq 200;
BA_REL_ "GenSigTimeoutTime" BU_SG_REL_ EPS SG_ 282 HAD_WorkingSt_NGP 200;
BA_REL_ "GenSigTimeoutTime" BU_SG_REL_ EPS SG_ 282 HAD_ErrorSt_NGP 200;
BA_REL_ "GenSigTimeoutTime" BU_SG_REL_ EPS SG_ 282 LiveCounter_HAD_3 200;
BA_REL_ "GenSigTimeoutTime" BU_SG_REL_ IBC SG_ 282 LiveCounter_HAD_3 200;
BA_REL_ "GenSigTimeoutTime" BU_SG_REL_ IBC SG_ 282 SECOC_FV_HAD_3 200;
BA_REL_ "GenSigTimeoutTime" BU_SG_REL_ IBC SG_ 282 SECOC_TMAC_HAD_3 200;
BA_REL_ "GenSigTimeoutTime" BU_SG_REL_ EPS SG_ 151 Checksum_HCU_2_10 100;
BA_REL_ "GenSigTimeoutTime" BU_SG_REL_ IBC SG_ 151 Checksum_HCU_2_10 100;
BA_REL_ "GenSigTimeoutTime" BU_SG_REL_ IBC SG_ 151 HCU_MCU1TMSpeed 100;
BA_REL_ "GenSigTimeoutTime" BU_SG_REL_ EPS SG_ 151 HCU_FrontWheelActTorque 100;
BA_REL_ "GenSigTimeoutTime" BU_SG_REL_ IBC SG_ 151 HCU_FrontWheelActTorque 100;
BA_REL_ "GenSigTimeoutTime" BU_SG_REL_ EPS SG_ 151 HCU_FrontWheelActTorqueSt 100;
BA_REL_ "GenSigTimeoutTime" BU_SG_REL_ IBC SG_ 151 HCU_FrontWheelActTorqueSt 100;
BA_REL_ "GenSigTimeoutTime" BU_SG_REL_ IBC SG_ 151 HCU_FrontWheelMaxDriveTorque 100;
BA_REL_ "GenSigTimeoutTime" BU_SG_REL_ IBC SG_ 151 HCU_FrontWheelMaxDriveTorqueSt 100;
BA_REL_ "GenSigTimeoutTime" BU_SG_REL_ IBC SG_ 151 HCU_FrontWheelMaxBrakeRegTorque 100;
BA_REL_ "GenSigTimeoutTime" BU_SG_REL_ IBC SG_ 151 HCU_FrontWheelMaxBrakeRegTorqSt 100;
BA_REL_ "GenSigTimeoutTime" BU_SG_REL_ IBC SG_ 151 HCU_FrontWheelBrakeRegTorque 100;
BA_REL_ "GenSigTimeoutTime" BU_SG_REL_ IBC SG_ 151 HCU_FrontWheelBrakeRegTorqueSt 100;
BA_REL_ "GenSigTimeoutTime" BU_SG_REL_ IBC SG_ 151 HCU_MCU2TMSpeed 100;
BA_REL_ "GenSigTimeoutTime" BU_SG_REL_ EPS SG_ 151 HCU_RearWheelActTorque 100;
BA_REL_ "GenSigTimeoutTime" BU_SG_REL_ IBC SG_ 151 HCU_RearWheelActTorque 100;
BA_REL_ "GenSigTimeoutTime" BU_SG_REL_ EPS SG_ 151 HCU_RearWheelActTorqueSt 100;
BA_REL_ "GenSigTimeoutTime" BU_SG_REL_ IBC SG_ 151 HCU_RearWheelActTorqueSt 100;
BA_REL_ "GenSigTimeoutTime" BU_SG_REL_ IBC SG_ 151 HCU_RearWheelMaxDriveTorque 100;
BA_REL_ "GenSigTimeoutTime" BU_SG_REL_ IBC SG_ 151 HCU_RearWheelMaxDriveTorqueSt 100;
BA_REL_ "GenSigTimeoutTime" BU_SG_REL_ IBC SG_ 151 HCU_RearWheelMaxBrakeRegTorque 100;
BA_REL_ "GenSigTimeoutTime" BU_SG_REL_ IBC SG_ 151 HCU_RearWheelMaxBrakeRegTorqSt 100;
BA_REL_ "GenSigTimeoutTime" BU_SG_REL_ IBC SG_ 151 HCU_RearWheelBrakeRegTorque 100;
BA_REL_ "GenSigTimeoutTime" BU_SG_REL_ IBC SG_ 151 HCU_RearWheelBrakeRegTorqueSt 100;
BA_REL_ "GenSigTimeoutTime" BU_SG_REL_ EPS SG_ 151 LiveCounter_HCU_2_10 100;
BA_REL_ "GenSigTimeoutTime" BU_SG_REL_ IBC SG_ 151 LiveCounter_HCU_2_10 100;
BA_REL_ "GenSigTimeoutTime" BU_SG_REL_ EPS SG_ 290 Checksum_HCU_2_12 200;
BA_REL_ "GenSigTimeoutTime" BU_SG_REL_ IBC SG_ 290 Checksum_HCU_2_12 200;
BA_REL_ "GenSigTimeoutTime" BU_SG_REL_ EPS SG_ 290 HCU2_LeverInfo 200;
BA_REL_ "GenSigTimeoutTime" BU_SG_REL_ IBC SG_ 290 HCU2_LeverInfo 200;
BA_REL_ "GenSigTimeoutTime" BU_SG_REL_ EPS SG_ 290 HCU_HighVoltageStatus 200;
BA_REL_ "GenSigTimeoutTime" BU_SG_REL_ IBC SG_ 290 HCU_HighVoltageStatus 200;
BA_REL_ "GenSigTimeoutTime" BU_SG_REL_ IBC SG_ 290 HCU_AutoParkingResponse_HPA 200;
BA_REL_ "GenSigTimeoutTime" BU_SG_REL_ IBC SG_ 290 HCU_AutoParkingResponse_AVP 200;
BA_REL_ "GenSigTimeoutTime" BU_SG_REL_ IBC SG_ 290 HCU_AutoParkingResponse_APA 200;
BA_REL_ "GenSigTimeoutTime" BU_SG_REL_ IBC SG_ 290 HCU_AutoParkingResponse_RPA 200;
BA_REL_ "GenSigTimeoutTime" BU_SG_REL_ IBC SG_ 290 HCU_CapabilitySt_AutoParking 200;
BA_REL_ "GenSigTimeoutTime" BU_SG_REL_ IBC SG_ 290 HCU_PowertrainErrorSt 200;
BA_REL_ "GenSigTimeoutTime" BU_SG_REL_ IBC SG_ 290 HCU_PowertrainWorkSt 200;
BA_REL_ "GenSigTimeoutTime" BU_SG_REL_ IBC SG_ 290 HCU_MCU1TorqueCtrlAvailableSt 200;
BA_REL_ "GenSigTimeoutTime" BU_SG_REL_ IBC SG_ 290 HCU_MCU2TorqueCtrlAvailableSt 200;
BA_REL_ "GenSigTimeoutTime" BU_SG_REL_ EPS SG_ 290 Livecounter_HCU_2_12 200;
BA_REL_ "GenSigTimeoutTime" BU_SG_REL_ IBC SG_ 290 Livecounter_HCU_2_12 200;
BA_REL_ "GenSigTimeoutTime" BU_SG_REL_ IBC SG_ 290 SECOC_FV_HCU_2_12 200;
BA_REL_ "GenSigTimeoutTime" BU_SG_REL_ IBC SG_ 290 SECOC_TMAC_HCU_2_12 200;
BA_REL_ "GenSigTimeoutTime" BU_SG_REL_ EPS SG_ 146 Checksum_HCU_2_2 100;
BA_REL_ "GenSigTimeoutTime" BU_SG_REL_ IBC SG_ 146 Checksum_HCU_2_2 100;
BA_REL_ "GenSigTimeoutTime" BU_SG_REL_ EPS SG_ 146 HCU_AccelerationPedalPosition 100;
BA_REL_ "GenSigTimeoutTime" BU_SG_REL_ IBC SG_ 146 HCU_AccelerationPedalPosition 100;
BA_REL_ "GenSigTimeoutTime" BU_SG_REL_ EPS SG_ 146 HCU_CalcAccelerationPedalPositio 100;
BA_REL_ "GenSigTimeoutTime" BU_SG_REL_ IBC SG_ 146 HCU_CalcAccelerationPedalPositio 100;
BA_REL_ "GenSigTimeoutTime" BU_SG_REL_ IBC SG_ 146 HCU_AccelerationPedalOverride 100;
BA_REL_ "GenSigTimeoutTime" BU_SG_REL_ EPS SG_ 146 LiveCounter_HCU_2_2 100;
BA_REL_ "GenSigTimeoutTime" BU_SG_REL_ IBC SG_ 146 LiveCounter_HCU_2_2 100;
BA_REL_ "GenSigTimeoutTime" BU_SG_REL_ IBC SG_ 264 Checksum_HCU_2_4 100;
BA_REL_ "GenSigTimeoutTime" BU_SG_REL_ IBC SG_ 264 HCU_DriverTorq_FrontWheel 100;
BA_REL_ "GenSigTimeoutTime" BU_SG_REL_ IBC SG_ 264 HCU_AutoDrivingResponseSt_L12 100;
BA_REL_ "GenSigTimeoutTime" BU_SG_REL_ IBC SG_ 264 HCU_AutoDrivingResponseSt_L3 100;
BA_REL_ "GenSigTimeoutTime" BU_SG_REL_ IBC SG_ 264 HCU_CapabilitySt_AutoDriving 100;
BA_REL_ "GenSigTimeoutTime" BU_SG_REL_ IBC SG_ 264 HCU_DriverTorq_RearWheel 100;
BA_REL_ "GenSigTimeoutTime" BU_SG_REL_ IBC SG_ 264 LiveCounter_HCU_2_4 100;
BA_REL_ "GenSigTimeoutTime" BU_SG_REL_ IBC SG_ 147 HCU_SlipContrlIntervention_Front 100;
BA_REL_ "GenSigTimeoutTime" BU_SG_REL_ IBC SG_ 147 HCU_SlipContrlIntervention_RearA 100;
BA_REL_ "GenSigTimeoutTime" BU_SG_REL_ IBC SG_ 147 HCU_SlopeContrlIntervention 100;
BA_REL_ "GenSigTimeoutTime" BU_SG_REL_ IBC SG_ 147 HCU_YawRateContrlIntervention 100;
BA_REL_ "GenSigTimeoutTime" BU_SG_REL_ RWS SG_ 147 HCU_EVReady 100;
BA_REL_ "GenSigTimeoutTime" BU_SG_REL_ IBC SG_ 640 ESCFunctionReq 1000;
BA_REL_ "GenSigTimeoutTime" BU_SG_REL_ IBC SG_ 640 HDCFunctionReq 1000;
BA_REL_ "GenSigTimeoutTime" BU_SG_REL_ IBC SG_ 640 CSTFunctionReq 1000;
BA_REL_ "GenSigTimeoutTime" BU_SG_REL_ IBC SG_ 670 HU_AVHFunctionReq 1000;
BA_REL_ "GenSigTimeoutTime" BU_SG_REL_ EPS SG_ 656 OdometerValue 1000;
BA_REL_ "GenSigTimeoutTime" BU_SG_REL_ IBC SG_ 656 OdometerValue 1000;
BA_REL_ "GenSigTimeoutTime" BU_SG_REL_ RWS SG_ 656 OdometerValue 1000;
BA_REL_ "GenSigTimeoutTime" BU_SG_REL_ EPS SG_ 308 Checksum_PDCM_YRS 200;
BA_REL_ "GenSigTimeoutTime" BU_SG_REL_ EPS SG_ 308 YawRate 200;
BA_REL_ "GenSigTimeoutTime" BU_SG_REL_ EPS SG_ 308 YRSSt 200;
BA_REL_ "GenSigTimeoutTime" BU_SG_REL_ EPS SG_ 308 Acceleration_X 200;
BA_REL_ "GenSigTimeoutTime" BU_SG_REL_ EPS SG_ 308 Acceleration_Y 200;
BA_REL_ "GenSigTimeoutTime" BU_SG_REL_ EPS SG_ 308 ErrorSt_YRS 200;
BA_REL_ "GenSigTimeoutTime" BU_SG_REL_ EPS SG_ 308 LiveCounter_PDCM_YRS 200;
BA_REL_ "GenSigTimeoutTime" BU_SG_REL_ IBC SG_ 190 Checksum_RVA_1 100;
BA_REL_ "GenSigTimeoutTime" BU_SG_REL_ RWS SG_ 190 Checksum_RVA_1 100;
BA_REL_ "GenSigTimeoutTime" BU_SG_REL_ RWS SG_ 190 SteerRearControlAngleReq_RVA 100;
BA_REL_ "GenSigTimeoutTime" BU_SG_REL_ RWS SG_ 190 SteerRearControlSt_RVA 100;
BA_REL_ "GenSigTimeoutTime" BU_SG_REL_ IBC SG_ 190 WorkingSt_RVA 100;
BA_REL_ "GenSigTimeoutTime" BU_SG_REL_ IBC SG_ 190 IBCControlAvailable_RVA 100;
BA_REL_ "GenSigTimeoutTime" BU_SG_REL_ IBC SG_ 190 Livecounter_RVA_1 100;
BA_REL_ "GenSigTimeoutTime" BU_SG_REL_ RWS SG_ 190 Livecounter_RVA_1 100;
BA_REL_ "GenSigTimeoutTime" BU_SG_REL_ IBC SG_ 190 SECOC_FV_RVA_1 100;
BA_REL_ "GenSigTimeoutTime" BU_SG_REL_ RWS SG_ 190 SECOC_FV_RVA_1 100;
BA_REL_ "GenSigTimeoutTime" BU_SG_REL_ IBC SG_ 190 SECOC_TMAC_RVA_1 100;
BA_REL_ "GenSigTimeoutTime" BU_SG_REL_ RWS SG_ 190 SECOC_TMAC_RVA_1 100;
BA_REL_ "GenSigTimeoutTime" BU_SG_REL_ RWS SG_ 686 TBOXTime_Hour 1000;
BA_REL_ "GenSigTimeoutTime" BU_SG_REL_ RWS SG_ 686 TBOXTime_Minute 1000;
BA_REL_ "GenSigTimeoutTime" BU_SG_REL_ RWS SG_ 686 TBOXTime_Second 1000;
BA_REL_ "GenSigTimeoutTime" BU_SG_REL_ RWS SG_ 686 TBOXTime_Year 1000;
BA_REL_ "GenSigTimeoutTime" BU_SG_REL_ RWS SG_ 686 TBOXTime_Month 1000;
BA_REL_ "GenSigTimeoutTime" BU_SG_REL_ RWS SG_ 686 TBOXTime_Day 1000;
BA_REL_ "GenSigTimeoutTime" BU_SG_REL_ RWS SG_ 686 TBOXTime_Millisecond 1000;
BA_REL_ "GenSigTimeoutTime" BU_SG_REL_ IBC SG_ 1376 SECOC_TripCounter 300000;
BA_REL_ "GenSigTimeoutTime" BU_SG_REL_ RBU SG_ 1376 SECOC_TripCounter 300000;
BA_REL_ "GenSigTimeoutTime" BU_SG_REL_ RWS SG_ 1376 SECOC_TripCounter 300000;
BA_REL_ "GenSigTimeoutTime" BU_SG_REL_ IBC SG_ 1376 SECOC_ResetCounter 300000;
BA_REL_ "GenSigTimeoutTime" BU_SG_REL_ RBU SG_ 1376 SECOC_ResetCounter 300000;
BA_REL_ "GenSigTimeoutTime" BU_SG_REL_ RWS SG_ 1376 SECOC_ResetCounter 300000;
BA_REL_ "GenSigTimeoutTime" BU_SG_REL_ IBC SG_ 1376 SECOC_Authenticator 300000;
BA_REL_ "GenSigTimeoutTime" BU_SG_REL_ RBU SG_ 1376 SECOC_Authenticator 300000;
BA_REL_ "GenSigTimeoutTime" BU_SG_REL_ RWS SG_ 1376 SECOC_Authenticator 300000;
BA_REL_ "GenSigTimeoutTime" BU_SG_REL_ EPS SG_ 280 Checksum_VDC_1 200;
BA_REL_ "GenSigTimeoutTime" BU_SG_REL_ IBC SG_ 280 Checksum_VDC_1 200;
BA_REL_ "GenSigTimeoutTime" BU_SG_REL_ IBC SG_ 280 VDC_AutoDrivingReq_L12 200;
BA_REL_ "GenSigTimeoutTime" BU_SG_REL_ IBC SG_ 280 VDC_DecelerationReqEnable_AEB 200;
BA_REL_ "GenSigTimeoutTime" BU_SG_REL_ EPS SG_ 280 VDC_SteeringTorqueRequestSign 200;
BA_REL_ "GenSigTimeoutTime" BU_SG_REL_ EPS SG_ 280 VDC_SteeringTorqueReqSt 200;
BA_REL_ "GenSigTimeoutTime" BU_SG_REL_ EPS SG_ 280 VDC_Intervention_LKA 200;
BA_REL_ "GenSigTimeoutTime" BU_SG_REL_ EPS SG_ 280 VDC_WorkingSt_LKA 200;
BA_REL_ "GenSigTimeoutTime" BU_SG_REL_ EPS SG_ 280 VDC_ErrorSt_LKA 200;
BA_REL_ "GenSigTimeoutTime" BU_SG_REL_ IBC SG_ 280 VDC_AccelerationPedalOverride 200;
BA_REL_ "GenSigTimeoutTime" BU_SG_REL_ IBC SG_ 280 VDC_WorkingSt_AEB_L12 200;
BA_REL_ "GenSigTimeoutTime" BU_SG_REL_ IBC SG_ 280 VDC_ErrorSt_AEB_L12 200;
BA_REL_ "GenSigTimeoutTime" BU_SG_REL_ IBC SG_ 280 VDC_ErrorSt_ACC_L12 200;
BA_REL_ "GenSigTimeoutTime" BU_SG_REL_ IBC SG_ 280 VDC_SpeedChangeRequest_L12 200;
BA_REL_ "GenSigTimeoutTime" BU_SG_REL_ IBC SG_ 280 VDC_DriveAwayReq_L12 200;
BA_REL_ "GenSigTimeoutTime" BU_SG_REL_ IBC SG_ 280 VDC_StopReq_L12 200;
BA_REL_ "GenSigTimeoutTime" BU_SG_REL_ IBC SG_ 280 VDC_WorkingSt_ACC_L12 200;
BA_REL_ "GenSigTimeoutTime" BU_SG_REL_ IBC SG_ 280 VDC_ABPReq_L12 200;
BA_REL_ "GenSigTimeoutTime" BU_SG_REL_ IBC SG_ 280 VDC_AWBReq_L12 200;
BA_REL_ "GenSigTimeoutTime" BU_SG_REL_ IBC SG_ 280 VDC_AWBlevel_L12 200;
BA_REL_ "GenSigTimeoutTime" BU_SG_REL_ IBC SG_ 280 VDC_BrakeModeReq_L12 200;
BA_REL_ "GenSigTimeoutTime" BU_SG_REL_ IBC SG_ 280 VDC_DrivedownModeReq_L12 200;
BA_REL_ "GenSigTimeoutTime" BU_SG_REL_ IBC SG_ 280 VDC_SecureRequest_L12 200;
BA_REL_ "GenSigTimeoutTime" BU_SG_REL_ EPS SG_ 280 VDC_ErrorSt_SACC 200;
BA_REL_ "GenSigTimeoutTime" BU_SG_REL_ IBC SG_ 280 VDC_DecelerationReq_AEB 200;
BA_REL_ "GenSigTimeoutTime" BU_SG_REL_ EPS SG_ 280 VDC_ErrorSt_VDC 200;
BA_REL_ "GenSigTimeoutTime" BU_SG_REL_ EPS SG_ 280 VDC_SteeringTorqueRequest 200;
BA_REL_ "GenSigTimeoutTime" BU_SG_REL_ EPS SG_ 280 VDC_AutoDrivingModeReq 200;
BA_REL_ "GenSigTimeoutTime" BU_SG_REL_ EPS SG_ 280 VDC_WorkingSt_SACC 200;
BA_REL_ "GenSigTimeoutTime" BU_SG_REL_ EPS SG_ 280 VDC_ErrorSt_EMA 200;
BA_REL_ "GenSigTimeoutTime" BU_SG_REL_ EPS SG_ 280 VDC_WorkingSt_EMA 200;
BA_REL_ "GenSigTimeoutTime" BU_SG_REL_ EPS SG_ 280 VDC_SteeringWheelAngleRequest 200;
BA_REL_ "GenSigTimeoutTime" BU_SG_REL_ EPS SG_ 280 VDC_SteeringWheelAngleSignReques 200;
BA_REL_ "GenSigTimeoutTime" BU_SG_REL_ EPS SG_ 280 VDC_SteeringWheelAngleControlReq 200;
BA_REL_ "GenSigTimeoutTime" BU_SG_REL_ EPS SG_ 280 VDC_AutoDrivingModeReq_EMA 200;
BA_REL_ "GenSigTimeoutTime" BU_SG_REL_ EPS SG_ 280 VDC_SteeringWheelBlendingGain 200;
BA_REL_ "GenSigTimeoutTime" BU_SG_REL_ EPS SG_ 280 VDC_SteeringMaxTorqueRequest 200;
BA_REL_ "GenSigTimeoutTime" BU_SG_REL_ IBC SG_ 280 VDC_WorkingSt_FCW 200;
BA_REL_ "GenSigTimeoutTime" BU_SG_REL_ IBC SG_ 280 VDC_ErrorSt_FCW 200;
BA_REL_ "GenSigTimeoutTime" BU_SG_REL_ EPS SG_ 280 VDC_ErrorSt_L3Backup 200;
BA_REL_ "GenSigTimeoutTime" BU_SG_REL_ IBC SG_ 280 VDC_ErrorSt_L3Backup 200;
BA_REL_ "GenSigTimeoutTime" BU_SG_REL_ EPS SG_ 280 VDC_WorkingSt_L3Backup 200;
BA_REL_ "GenSigTimeoutTime" BU_SG_REL_ EPS SG_ 280 LiveCounter_VDC_1 200;
BA_REL_ "GenSigTimeoutTime" BU_SG_REL_ IBC SG_ 280 LiveCounter_VDC_1 200;
VAL_ 256 ADV_ErrorSt_EPS 1 "Error" 0 "No Error" ;
VAL_ 256 ADV_AutoParkingModeReq 7 "Reserved" 6 "Reserved" 5 "Reserved" 4 "Reserved" 3 "AVP" 2 "RPA" 1 "APA" 0 "No request" ;
VAL_ 256 ADV_AutoParkingRequestSt 3 "Reserved" 2 "Auto Parking Active" 1 "Auto Parking Request" 0 "No Request" ;
VAL_ 256 APA_DriverInterventionSt 1 "Intervention" 0 "No_Intervention" ;
VAL_ 256 ADV_ErrorSt_APA 3 "Reserved" 2 "Error" 1 "Derate" 0 "Normal" ;
VAL_ 256 ADV_ErrorSt_RPA 3 "Reserved" 2 "Error" 1 "Derate" 0 "Normal" ;
VAL_ 256 ADV_ErrorSt_AVP 3 "Reserved" 2 "Error" 1 "Derate" 0 "Normal" ;
VAL_ 256 ADV_ErrorSt_RVA 3 "Reserved" 2 "Critical Error" 1 "General Error" 0 "No Error" ;
VAL_ 256 ADV_WorkingSt_APA 7 "Reserved" 6 "Reserved" 5 "Reserved" 4 "Exit" 3 "Active" 2 "Available" 1 "Standby" 0 "Off" ;
VAL_ 256 ADV_WorkingSt_RPA 7 "Reserved" 6 "Reserved" 5 "Reserved" 4 "Exit" 3 "Active" 2 "Available" 1 "Standby" 0 "Off" ;
VAL_ 256 ADV_WorkingSt_AVP 7 "Reserved" 6 "Reserved" 5 "Reserved" 4 "Exit" 3 "Active" 2 "Available" 1 "Standby" 0 "Off" ;
VAL_ 256 APA_SecureRequest 1 "Request" 0 "No_Request" ;
VAL_ 256 APA_AutoParkingReq 1 "Request" 0 "No_Request" ;
VAL_ 256 APA_DirectionCmd 3 "Not_Used" 2 "Backward" 1 "Forward" 0 "No_Request" ;
VAL_ 256 ADV_SteeringWheelAngleRequest 32767 "SNA" ;
VAL_ 256 ADV_SteeringWheelAngleSignReques 3 "Reserved" 2 "Right (Negative)" 1 "Left (Positive)" 0 "No Request" ;
VAL_ 256 ADV_SteeringWheelAngleControlReq 3 "Reserved" 2 "Reserved" 1 "EPS control request" 0 "No Request" ;
VAL_ 256 ADV_RearWheelAngleRequestSt 3 "Reserved" 2 "Auto Parking Active" 1 "Auto Parking Request" 0 "No Request" ;
VAL_ 256 ADV_RearWheelAngleRequest 4095 "SNA" ;
VAL_ 256 APA_BrakeFunctionMode 15 "Reserved" 14 "Reserved" 13 "Reserved" 12 "Reserved" 11 "Reserved" 10 "Reserved" 9 "Reserved" 8 "Reserved" 7 "Reserved" 6 "Reserved" 5 "Reserved" 4 "HPA" 3 "AVP(L4)" 2 "RPA(L23)" 1 "APA(L12)" 0 "No_ActIve" ;
VAL_ 256 APA_FailureBrakeMode 7 "Not_Used" 6 "Not_Used" 5 "Not_Used" 4 "Emergency" 3 "Comfort_brake_type_3" 2 "Comfort_brake_type_2" 1 "Comfort_barke_type_1" 0 "Idle_No_Braking" ;
VAL_ 546 AmbientTemp 255 "SNA" ;
VAL_ 586 DoorSt_FL 1 "Open" 0 "Close" ;
VAL_ 532 DMS_ESCModeChangeCmd 15 "Reserved" 14 "Reserved" 13 "Reserved" 12 "Reserved" 11 "Reserved" 10 "Reserved" 9 "Reserved" 8 "Extreme" 7 "Sport" 6 "Sand" 5 "MUD_Ruts" 4 "Off_road" 3 "Snow" 2 "Eco" 1 "Auto" 0 "Inactive" ;
VAL_ 532 DMS_EPSModeChangeCmd 3 "Comfort" 2 "Sport" 1 "Auto" 0 "Inactive" ;
VAL_ 580 MemoryMode_DSCU 7 "Reserved" 6 "Reserved" 5 "Intial" 4 "Seat auto forward" 3 "Seat auto backward" 2 "Read" 1 "Memory" 0 "No operation" ;
VAL_ 580 SeatBeltSt_DSCU 3 "Reserved" 2 "Reserved" 1 "Buckled" 0 "Unbuckled" ;
VAL_ 580 FLSeatBackAngle 31 "SNA" ;
VAL_ 233 PbcOutActuatorState_M 7 "HapPrepared" 6 "Unknown" 5 "CompletelyReleased" 4 "Releasing" 3 "Applying" 2 "Released" 1 "HoldApplied" 0 "ParkApplied" ;
VAL_ 233 PbcOutPadAdjustmentRequest_M 1 "Request" 0 "No_Request" ;
VAL_ 233 PbcInHostAvailability_M 3 "ApplyAndRelease" 2 "Release" 1 "Apply" 0 "None" ;
VAL_ 233 PbcInApplyReleaseRequest_M 15 "Not_Used_15" 14 "Not_Used_14" 13 "Not_Used_13" 12 "Not_Used_12" 11 "Not_Used_11" 10 "Not_Used_10" 9 "Not_Used_9" 8 "HapPreparation" 7 "EmergencyParkApply" 6 "PadAdjustment" 5 "RollerbenchApply" 4 "DynamicApply" 3 "Release" 2 "HoldApply" 1 "ParkApply" 0 "None" ;
VAL_ 233 PbcInRollerbenchActive_M 1 "Inactive" 0 "Active" ;
VAL_ 233 PbcInDriveAwayIntentionIndicatio 1 "Indicated" 0 "Not Indicated" ;
VAL_ 233 PbcEnableLineLock_M 1 "True" 0 "False" ;
VAL_ 233 PbcEnableLineRelease_M 1 "True" 0 "False" ;
VAL_ 233 EpbDegradedMode_M 7 "Not_Used_7" 6 "Not_Used_6" 5 "Not_Used_5" 4 "DegrationModeE" 3 "DegrationModeD" 2 "DegrationModeC" 1 "DegrationModeB" 0 "DegrationModeA" ;
VAL_ 233 PbcDynApplyControlState_M 15 "Not_Used_15" 14 "Not_Used_14" 13 "Not_Used_13" 12 "Not_Used_12" 11 "Not_Used_11" 10 "Not_Used_10" 9 "ePbcDynAppCntrlStErr" 8 "ePbcDynAppCntrlStStpApp" 7 "ePbcDynAppCntrlStRestrtEn" 6 "ePbcDynAppCntrlStRestrt" 5 "ePbcDynAppCntrlStHld" 4 "ePbcDynAppCntrlStIdl" 3 "ePbcDynAppCntrlStRsh" 2 "ePbcDynAppCntrlStChgDirctn" 1 "ePbcDynAppCntrlStStrt" 0 "ePbcDynAppCntrlStInactv" ;
VAL_ 233 PbcRollerbenchApplyControlState_ 15 "Not_Used_15" 14 "Not_Used_14" 13 "ePbcRBAppCntrlStExit" 12 "ePbcRBAppCntrlStLoad" 11 "ePbcRBAppCntrlStRsh2" 10 "ePbcRBAppCntrlStMtrStkChk" 9 "ePbcRBAppCntrlStErr" 8 "ePbcRBAppCntrlStStpApp" 7 "ePbcRBAppCntrlStRestrtEn" 6 "ePbcRBAppCntrlStRestrt" 5 "ePbcRBAppCntrlStHld" 4 "ePbcRBAppCntrlStIdl" 3 "ePbcRBAppCntrlStRsh" 2 "ePbcRBAppCntrlStChgDirctn" 1 "ePbcRBAppCntrlStStrt" 0 "ePbcRBAppCntrlStInactv" ;
VAL_ 233 IsRelTchPt_M 1 "True" 0 "False" ;
VAL_ 233 IsRWAAppEn_M 1 "True" 0 "False" ;
VAL_ 233 IsRWARelEn_M 1 "True" 0 "False" ;
VAL_ 233 PbcRWAControlState_M 15 "ePbcRWACntrlStMtrStkChk" 14 "ePbcRWACntrlStErr" 13 "ePbcRWACntrlStRelDsbl" 12 "ePbcRWACntrlStRelHld" 11 "ePbcRWACntrlStAppHld" 10 "ePbcRWACntrlStStpRel" 9 "ePbcRWACntrlStRelDly" 8 "ePbcRWACntrlStStpApp" 7 "ePbcRBAppCntrlStRestrtEn" 6 "ePbcRWACntrlStResync" 5 "ePbcRWACntrlStHldInit" 4 "ePbcRWACntrlStIdl" 3 "ePbcRWACntrlStRsh" 2 "ePbcRWACntrlStChgDirctn" 1 "ePbcRWACntrlStStrt" 0 "ePbcRWACntrlStInactv" ;
VAL_ 206 EPBMaster_Switch_1 3 "Not_Used_3" 2 "Down" 1 "Up" 0 "No_press" ;
VAL_ 206 RWU_Active_Master 1 "Active" 0 "Inactive" ;
VAL_ 206 SRU_Active_Master 1 "Active" 0 "Inactive" ;
VAL_ 206 LampCmd_EPBMaster_1 3 "Not_Used" 2 "On" 1 "Flash" 0 "Off" ;
VAL_ 206 BrakeForceNotEnoughWarning_EPBMa 1 "Warning" 0 "No_warning" ;
VAL_ 206 GradientHighWarning_EPBMaster_1 1 "Warning" 0 "No_warning" ;
VAL_ 206 EPBMasterDecelerationRequest 4095 "SNA" ;
VAL_ 206 StatusEPBMasterDecelerationReque 1 "Deceleration_Request" 0 "No_Request" ;
VAL_ 206 BrakeLightCtrlCmd_EPBMaster_1 1 "Illuminate" 0 "Not_illuminate" ;
VAL_ 206 WorkingSt_EPBMaster_1 7 "Not_Used_7" 6 "Not_Used_6" 5 "Not_Used_5" 4 "Applying" 3 "Unknown" 2 "Applied" 1 "Releasing" 0 "Released" ;
VAL_ 206 ErrorSt_EPBMaster_1 7 "Not_Used_7" 6 "Not_Used_6" 5 "Not_Used_5" 4 "Test_mode" 3 "Both_Sides_Error" 2 "Right_Side_Error" 1 "Left_Side_Error" 0 "No_Error" ;
VAL_ 282 HAD_AutoDrivingReq_L3 3 "Not_Used" 2 "L3Request" 1 "L1L2Request" 0 "No_Request" ;
VAL_ 282 HAD_SpeedChangeRequest_L3 2047 "SNA" ;
VAL_ 282 HAD_TimeGapSetting 7 "Reserved" 6 "Reserved" 5 "Reserved" 4 "Reserved" 3 "TimeGap4" 2 "TimeGap3" 1 "TimeGap2" 0 "TimeGap1" ;
VAL_ 282 NOP_RearWheelAngleRequest 4095 "SNA" ;
VAL_ 282 NOP_RearWheelAngleRequestSt 1 "Valid" 0 "Invalid" ;
VAL_ 282 NOP_RearWheelReturnReq 1 "Valid" 0 "Invalid" ;
VAL_ 282 HAD_ObjectDetection 1 "Target_object_detected" 0 "No_object" ;
VAL_ 282 HAD_TakeOverReq 1 "Request" 0 "No_request" ;
VAL_ 282 HAD_CruiseSpeedSetting_ACC 255 "SNA" ;
VAL_ 282 HAD_SysTextinfo 15 "Radar_is_covered" 14 "Radar_not_calibration" 13 "SACC_cancelled_autoly" 12 "LCA_cancelled_autoly" 11 "ACC_cancelled_autoly" 10 "Speed_is_less_than_10,unable_to_active_ACC" 9 "Camera_is_not_calibration" 8 "Camera_is_polluted,_please_clean_the_camera_cover." 7 "System_initial" 6 "Bad_weather,system_can_not_work" 5 "Because__driver_cancel_operation" 4 "Because_ESC_interven,_ACC_cancelled" 3 "Stop-Go_clue_-step_gas_pedal_or_press_resume_key" 2 "Radar_error" 1 "Conditions_not_satisfied,_unable_to_active_ACC" 0 "No_display" ;
VAL_ 282 HAD_LDWModeInd 3 "Not_Used" 2 "LDW+LKA" 1 "LDW+Vibration" 0 "LDW_only" ;
VAL_ 282 HAD_AutoLightModeReq 1 "Request" 0 "No_request" ;
VAL_ 282 HAD_HazardWarningLampRequest 1 "Request" 0 "No_request" ;
VAL_ 282 HAD_WorkingSt_LDW 3 "Error" 2 "Active" 1 "Standby" 0 "Off" ;
VAL_ 282 HAD_WarningCmd_LDW 3 "Not_Used" 2 "RightWarning" 1 "LeftWarning" 0 "Inactive" ;
VAL_ 282 HAD_LDWLaneDetectSt 3 "Both_side_lane_marks_detected" 2 "Right_side_lane_mark_detected" 1 "Left_side_lane_mark_detected" 0 "Neither_side_lane_mark_detected" ;
VAL_ 282 HAD_SensitivityInd_LDW 3 "Not_Used" 2 "High" 1 "Normal" 0 "Low" ;
VAL_ 282 HAD_ErrorSt_LDW 1 "Error" 0 "No_Error" ;
VAL_ 282 HAD_WorkingSt_FCW 3 "Not_Used" 2 "Active" 1 "Standby" 0 "Off" ;
VAL_ 282 HAD_DriveAwayReq_L3 1 "Request" 0 "No_Request" ;
VAL_ 282 HAD_StopReq_L3 1 "Request" 0 "No_Request" ;
VAL_ 282 HAD_AccelerationPedalOverride 1 "Active" 0 "Inactive" ;
VAL_ 282 HAD_SensitivityInd_FCW 3 "Not_Used" 2 "High" 1 "Normal" 0 "Low" ;
VAL_ 282 HAD_FCWModeInd 3 "Not_Used" 2 "FCW+EAB" 1 "Not_Used" 0 "FCW_only" ;
VAL_ 282 HAD_WiperAutoLeverReq 1 "Request" 0 "No_request" ;
VAL_ 282 HAD_VASFunctionInd 1 "On" 0 "Off" ;
VAL_ 282 HAD_SACCNotSatisfiedCondition 7 "Abnormal_exited_for_driver_not_taking_over,power_on_again_and_try_then" 6 "AutoParking_active" 5 "The_door_is_open" 4 "Hands_off_" 3 "Turning_around" 2 "Tite_your_seatbelt" 1 "Speed_too_high" 0 "Inactive" ;
VAL_ 282 HAD_LDW_SpeechControlFeedback 7 "Reserved" 6 "Reserved" 5 "Reserved" 4 "On_Failure" 3 "On_Success" 2 "Off_Failure" 1 "Off_Success" 0 "Inactive" ;
VAL_ 282 HAD_IFCSystemError 3 "Not_Used" 2 "Camera_is_covered,please_clean" 1 "System_error" 0 "No_error" ;
VAL_ 282 HAD_IFCCalibrationStatus 3 "Not_Calibrationed" 2 "Calibration_Failed" 1 "Calibrating" 0 "Calibration_Success" ;
VAL_ 282 HAD_WarningCmd_VAS 1 "Active" 0 "Inactive" ;
VAL_ 282 HAD_LeftTurningLampRequest 3 "Not_Used" 2 "On" 1 "Off" 0 "No_request" ;
VAL_ 282 HAD_RightTurningLampRequest 3 "Not_Used" 2 "On" 1 "Off" 0 "No_request" ;
VAL_ 282 HAD_ValetModeStatus 1 "On" 0 "Off" ;
VAL_ 282 HAD_BrakeModeReq_L3 3 "Not_Used" 2 "Emergency" 1 "Comfortable" 0 "Not_Used" ;
VAL_ 282 HAD_DrivedownModeReq_L3 3 "Not_Used" 2 "Immediate_Off" 1 "Fast_Off" 0 "Soft_Off" ;
VAL_ 282 HAD_SecureRequest_L3 3 "Not_Used" 2 "Not_Used" 1 "Secure_request" 0 "No_request" ;
VAL_ 282 HAD_ErrorSt_AutoDriving_L3 1 "Error" 0 "No_Error" ;
VAL_ 282 HAD_WorkingSt_NOP 7 "Reserved" 6 "Reserved" 5 "Reserved" 4 "Exit" 3 "Active" 2 "Available" 1 "Standby" 0 "Off" ;
VAL_ 282 HAD_ErrorSt_NOP 3 "Not_Used" 2 "Error" 1 "Derate" 0 "Normal" ;
VAL_ 282 HAD_ErrorSt_HAD 1 "Error" 0 "No_Error" ;
VAL_ 282 HAD_AutoDrivingModeReq_NOP 1 "Request" 0 "No_Request" ;
VAL_ 282 HAD_AutoDrivingModeReq_NGP 1 "Request" 0 "No_Request" ;
VAL_ 282 HAD_SteeringWheelBlendingGain 255 "SNA" ;
VAL_ 282 HAD_SteeringWheelAngleRequest 32767 "SNA" ;
VAL_ 282 HAD_SteeringWheelAngleSignReques 3 "Reserved" 2 "Right (Negative)" 1 "Left (Positive)" 0 "No Request" ;
VAL_ 282 HAD_SteeringWheelAngleControlReq 3 "Reserved" 2 "Reserved" 1 "EPS control request" 0 "No Request" ;
VAL_ 282 HAD_WorkingSt_NGP 7 "Reserved" 6 "Reserved" 5 "Reserved" 4 "Exit" 3 "Active" 2 "Available" 1 "Standby" 0 "Off" ;
VAL_ 282 HAD_ErrorSt_NGP 3 "Not_Used" 2 "Error" 1 "Derate" 0 "Normal" ;
VAL_ 151 HCU_MCU1TMSpeed 65535 "SNA" ;
VAL_ 151 HCU_FrontWheelActTorque 16383 "SNA" ;
VAL_ 151 HCU_FrontWheelActTorqueSt 1 "Failure" 0 "No_failure" ;
VAL_ 151 HCU_FrontWheelMaxDriveTorque 8191 "SNA" ;
VAL_ 151 HCU_FrontWheelMaxDriveTorqueSt 1 "Failure" 0 "No_failure" ;
VAL_ 151 HCU_FrontWheelMaxBrakeRegTorque 8191 "SNA" ;
VAL_ 151 HCU_FrontWheelMaxBrakeRegTorqSt 1 "Failure" 0 "No_failure" ;
VAL_ 151 HCU_FrontWheelBrakeRegTorque 8191 "SNA" ;
VAL_ 151 HCU_FrontWheelBrakeRegTorqueSt 1 "Failure" 0 "No_failure" ;
VAL_ 151 HCU_MCU2TMSpeed 65535 "SNA" ;
VAL_ 151 HCU_RearWheelActTorque 16383 "SNA" ;
VAL_ 151 HCU_RearWheelActTorqueSt 1 "Failure" 0 "No_failure" ;
VAL_ 151 HCU_RearWheelMaxDriveTorque 8191 "SNA" ;
VAL_ 151 HCU_RearWheelMaxDriveTorqueSt 1 "Failure" 0 "No_failure" ;
VAL_ 151 HCU_RearWheelMaxBrakeRegTorque 8191 "SNA" ;
VAL_ 151 HCU_RearWheelMaxBrakeRegTorqSt 1 "Failure" 0 "No_failure" ;
VAL_ 151 HCU_RearWheelBrakeRegTorque 8191 "SNA" ;
VAL_ 151 HCU_RearWheelBrakeRegTorqueSt 1 "Failure" 0 "No_failure" ;
VAL_ 290 HCU2_LeverInfo 7 "Invalid_Value" 6 "Not_Used" 5 "No_connection" 4 "Not_Used" 3 "D" 2 "N" 1 "R" 0 "P" ;
VAL_ 290 HCU_HighVoltageStatus 1 "ON" 0 "OFF" ;
VAL_ 290 HCU_AutoParkingResponse_HPA 1 "Response" 0 "No_response" ;
VAL_ 290 HCU_AutoParkingResponse_AVP 1 "Response" 0 "No_response" ;
VAL_ 290 HCU_AutoParkingResponse_APA 1 "Response" 0 "No_response" ;
VAL_ 290 HCU_AutoParkingResponse_RPA 1 "Response" 0 "No_response" ;
VAL_ 290 HCU_CapabilitySt_AutoParking 3 "Not_Used" 2 "Fault" 1 "Reduced" 0 "Normal" ;
VAL_ 290 HCU_PowertrainErrorSt 1 "Error" 0 "No Error" ;
VAL_ 290 HCU_PowertrainWorkSt 7 "Not_Used_7" 6 "Not_Used_6" 5 "FrontDrive" 4 "RearDrive_to_FourDrive" 3 "FourDrive_to_RearDrive" 2 "AllFourDrive" 1 "RearDrive" 0 "Initiation" ;
VAL_ 290 HCU_MCU1TorqueCtrlAvailableSt 1 "Not Available" 0 "Available" ;
VAL_ 290 HCU_MCU2TorqueCtrlAvailableSt 1 "Not Available" 0 "Available" ;
VAL_ 146 HCU_EPBLeverRequest 7 "Invalid_Value" 6 "Not_Used_5" 5 "Not_Used_4" 4 "Not_Used_3" 3 "D" 2 "N" 1 "R" 0 "P" ;
VAL_ 146 HCU_AccelerationPedalPosition 255 "SNA" ;
VAL_ 146 HCU_CalcAccelerationPedalPositio 255 "SNA" ;
VAL_ 146 HCU_AccelerationPedalOverride 1 "Active" 0 "Inactive" ;
VAL_ 146 HCU_KickdownReq 1 "Active" 0 "Inactive" ;
VAL_ 146 LiveCounter_HCU_2_2 15 "SNA" ;
VAL_ 264 HCU_DriverTorq_FrontWheel 65535 "SNA" ;
VAL_ 264 HCU_AutoDrivingResponseSt_L12 1 "Response" 0 "No_response" ;
VAL_ 264 HCU_AutoDrivingResponseSt_L3 1 "Response" 0 "No_response" ;
VAL_ 264 HCU_CruiseControlSt 3 "Invalid_Value" 2 "Active" 1 "Stand_By" 0 "Inactive" ;
VAL_ 264 HCU_CapabilitySt_AutoDriving 3 "Not_Used" 2 "Fault" 1 "Reduced" 0 "Normal" ;
VAL_ 264 HCU_DriverTorq_RearWheel 65535 "SNA" ;
VAL_ 264 HCU_GradientAccelerationPedal 255 "SNA" ;
VAL_ 147 HCU_SlipContrlIntervention_Front 1 "Intervention" 0 "No Intervention" ;
VAL_ 147 HCU_SlipContrlIntervention_RearA 1 "Intervention" 0 "No Intervention" ;
VAL_ 147 HCU_SlopeContrlIntervention 1 "Intervention" 0 "No Intervention" ;
VAL_ 147 HCU_YawRateContrlIntervention 1 "Intervention" 0 "No Intervention" ;
VAL_ 147 HCU_EVReady 3 "Not_Used" 2 "Enable_Running" 1 "Preparing" 0 "Not_useable" ;
VAL_ 640 EPBFunctionSet 3 "Reserved" 2 "Lock" 1 "Release" 0 "Inactive" ;
VAL_ 640 EPBAutoLockFunctionReq 3 "Not_Used" 2 "On" 1 "Off" 0 "Inactive" ;
VAL_ 640 ESCFunctionReq 3 "Not_Used" 2 "On" 1 "Off" 0 "Inactive" ;
VAL_ 640 HDCFunctionReq 3 "Not_Used" 2 "On" 1 "Off" 0 "Inactive" ;
VAL_ 640 CSTFunctionReq 3 "Not_Used" 2 "On" 1 "Off" 0 "Inactive" ;
VAL_ 670 HU_AVHFunctionReq 3 "Not_Used" 2 "On" 1 "Off" 0 "Inactive" ;
VAL_ 656 OdometerValue 33554431 "SNA" ;
VAL_ 308 YawRate 4095 "SNA" ;
VAL_ 308 YRSSt 1 "Not Calibrated" 0 "Calibrated" ;
VAL_ 308 Acceleration_X 2047 "SNA" ;
VAL_ 308 Acceleration_Y 2047 "SNA" ;
VAL_ 308 ErrorSt_YRS 1 "Error" 0 "No Error" ;
VAL_ 190 SteerRearControlAngleReq_RVA 4095 "SNA" ;
VAL_ 190 SteerRearControlSt_RVA 3 "Error" 2 "Request" 1 "Not Request" 0 "Initial" ;
VAL_ 190 WorkingSt_RVA 7 "Invalid value" 6 "Reserved" 5 "LKA Control" 4 "NOP Control" 3 "SACC Control" 2 "APA Control" 1 "IBC Control" 0 "Not Control" ;
VAL_ 190 BehaviorMode_RVA 7 "Invalid value" 6 "Reserved" 5 "Reserved" 4 "Fail" 3 "Temporary inhabit" 2 "Active" 1 "Standby" 0 "Initial" ;
VAL_ 190 ErrorSt_RVA 3 "Reserved" 2 "Critical Error" 1 "General Error" 0 "No Error" ;
VAL_ 190 IBCControlAvailable_RVA 1 "Availbale" 0 "Not Available" ;
VAL_ 190 APAControlSt_RVA 1 "Enable" 0 "Disable" ;
VAL_ 190 APAAbortFeedback_RVA 31 "Reserved" 30 "Reserved" 29 "Reserved" 28 "Reserved" 27 "Reserved" 26 "Reserved" 25 "Reserved" 24 "Reserved" 23 "Reserved" 22 "Reserved" 21 "Reserved" 20 "Reserved" 19 "Reserved" 18 "Reserved" 17 "Reserved" 16 "Reserved" 15 "Reserved" 14 "Reserved" 13 "Reserved" 12 "Reserved" 11 "RWS internal failure with limited steering assistance" 10 "RWS system critical failure no steering assistance" 9 "CAN Bus Off" 8 "Rear Steering Wheel Angle exceeds limits" 7 "RWS control active received without handshaking" 6 "RVA control Req received when in control" 5 "Vehicle Speed exceeds limits when in control" 4 "RVA Handshaking time out£®t2£©" 3 "APA System signal invalid or time out" 2 "Vehicle Speed invalid or time out" 1 "Vehicle Speed exceeds limits before control" 0 "No driving interuption" ;
VAL_ 190 SACCControlSt_RVA 3 "Occupy" 2 "Active" 1 "Enable" 0 "Disable" ;
VAL_ 190 LKAControlSt_RVA 3 "Occupy" 2 "Active" 1 "Enable" 0 "Disable" ;
VAL_ 190 NOPControlSt_RVA 3 "Occupy" 2 "Active" 1 "Enable" 0 "Disable" ;
VAL_ 686 TBOXTime_Hour 31 "SNA" ;
VAL_ 686 TBOXTime_Minute 63 "SNA" ;
VAL_ 686 TBOXTime_Second 63 "SNA" ;
VAL_ 686 TBOXTime_Year 127 "SNA" ;
VAL_ 686 TBOXTime_Month 15 "SNA" ;
VAL_ 686 TBOXTime_Day 127 "SNA" ;
VAL_ 686 TBOXTime_Millisecond 1023 "SNA" ;
VAL_ 280 VDC_AutoDrivingReq_L12 3 "Not_Used" 2 "L3 Request" 1 "L1L2Request" 0 "No_Request" ;
VAL_ 280 VDC_DecelerationReqEnable_AEB 3 "Not_Used" 2 "Request" 1 "Not_Used" 0 "No_Request" ;
VAL_ 280 VDC_SteeringTorqueRequestSign 1 "Right_Negative" 0 "Left_Positive" ;
VAL_ 280 VDC_SteeringTorqueReqSt 1 "Torque_Request" 0 "No_Request" ;
VAL_ 280 VDC_Intervention_LKA 3 "Not_Used" 2 "Right_Intervention" 1 "Left_Intervention" 0 "Not_Intervention" ;
VAL_ 280 VDC_WorkingSt_LKA 3 "Error" 2 "Active" 1 "Standby" 0 "Off" ;
VAL_ 280 VDC_ErrorSt_LKA 1 "Error" 0 "No_Error" ;
VAL_ 280 VDC_AccelerationPedalOverride 1 "Active" 0 "Inactive" ;
VAL_ 280 VDC_WorkingSt_AEB_L12 3 "Not_Used" 2 "Active" 1 "Standby" 0 "Off" ;
VAL_ 280 VDC_ErrorSt_AEB_L12 1 "Error" 0 "No_Error" ;
VAL_ 280 VDC_ErrorSt_ACC_L12 1 "Error" 0 "No_Error" ;
VAL_ 280 VDC_SpeedChangeRequest_L12 2047 "SNA" ;
VAL_ 280 VDC_DriveAwayReq_L12 1 "Request" 0 "No_Request" ;
VAL_ 280 VDC_StopReq_L12 1 "Request" 0 "No_Request" ;
VAL_ 280 VDC_WorkingSt_ACC_L12 7 "Not_Used_3" 6 "Not_Used_2" 5 "Not_Used_1" 4 "Shutoff" 3 "Override" 2 "Active" 1 "Stand_By" 0 "Off" ;
VAL_ 280 VDC_TakeOverTip_LCA 1 "Active" 0 "Inactive" ;
VAL_ 280 VDC_ABPReq_L12 1 "Request" 0 "No_Request" ;
VAL_ 280 VDC_AWBReq_L12 1 "Request" 0 "No_Request" ;
VAL_ 280 VDC_AWBlevel_L12 7 "Not_Used_3" 6 "Not_Used_2" 5 "Not_Used_1" 4 "Level4" 3 "Level3" 2 "Level2" 1 "Level1" 0 "Inactive" ;
VAL_ 280 VDC_CruiseModeFunctionInd 3 "Reserved" 2 "SACC" 1 "ACC" 0 "Off" ;
VAL_ 280 VDC_BrakeModeReq_L12 3 "Not_Used" 2 "Emergency" 1 "Comfortable" 0 "Reserved" ;
VAL_ 280 VDC_DrivedownModeReq_L12 3 "Not_Used" 2 "Immediate_Off" 1 "Fast_Off" 0 "Soft_Off" ;
VAL_ 280 VDC_SecureRequest_L12 1 "Request" 0 "No_Request" ;
VAL_ 280 VDC_AEBSensitivity_L12 3 "High" 2 "Normal" 1 "Low" 0 "Inactive" ;
VAL_ 280 VDC_ErrorSt_LCA 1 "Error" 0 "No_Error" ;
VAL_ 280 VDC_AutoDrivingReq 3 "Not_Used" 2 "L3" 1 "L12" 0 "Inactive" ;
VAL_ 280 VDC_AutoDrivingLevel 3 "Not_Used" 2 "L4" 1 "L3" 0 "L12" ;
VAL_ 280 VDC_HandsOffTip_LCA 3 "Not_Used" 2 "Level2" 1 "Level1" 0 "Inactive" ;
VAL_ 280 VDC_ErrorSt_SACC 3 "Not_Used" 2 "Error" 1 "Derate" 0 "Normal" ;
VAL_ 280 VDC_DecelerationReq_AEB 1023 "SNA" ;
VAL_ 280 VDC_WorkingSt_LCA 7 "Not_Used" 6 "Recoverable-SteeeringOverride" 5 "Recoverable-LaneLineDisappearing" 4 "Exit" 3 "Active" 2 "Available" 1 "Standby" 0 "Off" ;
VAL_ 280 VDC_LDWSteeringVibrationReq 1 "Request" 0 "No_Request" ;
VAL_ 280 VDC_ErrorSt_VDC 1 "Error" 0 "No_Error" ;
VAL_ 280 VDC_SteeringTorqueRequest 1023 "SNA" ;
VAL_ 280 VDC_AutoDrivingModeReq 7 "Reserved" 6 "Reserved" 5 "L3Backup" 4 "Reserved" 3 "Reserved" 2 "SACC" 1 "LKA" 0 "No_request" ;
VAL_ 280 VDC_WorkingSt_SACC 7 "Reserved" 6 "Reserved" 5 "Reserved" 4 "Exit" 3 "Active" 2 "Available" 1 "Standby" 0 "Off" ;
VAL_ 280 VDC_WorkingSt_DCLC 7 "Reserved" 6 "Reserved" 5 "Reserved" 4 "Exit" 3 "Active" 2 "Available" 1 "Standby" 0 "Off" ;
VAL_ 280 VDC_ErrorSt_EMA 1 "Error" 0 "No_Error" ;
VAL_ 280 VDC_WorkingSt_EMA 7 "Reserved" 6 "Reserved" 5 "Reserved" 4 "Exit" 3 "Active" 2 "Available" 1 "Standby" 0 "Off" ;
VAL_ 280 VDC_SteeringWheelAngleRequest 32767 "SNA" ;
VAL_ 280 SACC_RearWheelAngleRequestSt 1 "Valid" 0 "Invalid" ;
VAL_ 280 VDC_SteeringWheelAngleSignReques 3 "Reserved" 2 "Right (Negative)" 1 "Left (Positive)" 0 "No Request" ;
VAL_ 280 VDC_SteeringWheelAngleControlReq 3 "Reserved" 2 "Reserved" 1 "EPS control request" 0 "No Request" ;
VAL_ 280 SACC_RearWheelReturnReq 1 "Valid" 0 "Invalid" ;
VAL_ 280 LKA_RearWheelAngleRequestSt 1 "Valid" 0 "Invalid" ;
VAL_ 280 LKA_RearWheelReturnReq 1 "Valid" 0 "Invalid" ;
VAL_ 280 VDC_AutoDrivingModeReq_EMA 1 "Request" 0 "No_Request" ;
VAL_ 280 VDC_SteeringWheelBlendingGain 255 "SNA" ;
VAL_ 280 VDC_SteeringMaxTorqueRequest 1023 "SNA" ;
VAL_ 280 SACC_RearWheelAngleRequest 4095 "SNA" ;
VAL_ 280 LKA_RearWheelAngleRequest 4095 "SNA" ;
VAL_ 280 VDC_WorkingSt_FCW 3 "Not_Used" 2 "Active" 1 "Standby" 0 "Off" ;
VAL_ 280 VDC_ErrorSt_FCW 1 "Error" 0 "No_Error" ;
VAL_ 280 VDC_ErrorSt_L3Backup 1 "Error" 0 "No_Error" ;
VAL_ 280 VDC_WorkingSt_L3Backup 7 "Reserved" 6 "Reserved" 5 "Reserved" 4 "Exit" 3 "Active" 2 "Available" 1 "Standby" 0 "Off" ;
